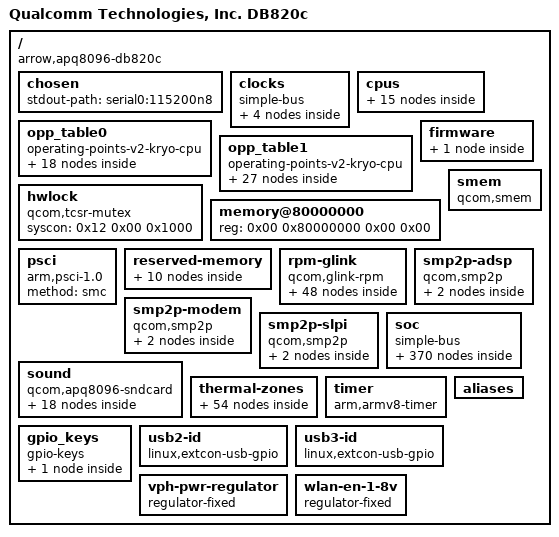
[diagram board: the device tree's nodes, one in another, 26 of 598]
/dts-v1/;

/ {
	interrupt-parent = <0x01>;
	#address-cells = <0x02>;
	#size-cells = <0x02>;
	model = "Qualcomm Technologies, Inc. DB820c";
	compatible = "arrow,apq8096-db820c\0qcom,apq8096-sbc\0qcom,apq8096";

	chosen {
		stdout-path = "serial0:115200n8";
	};

	clocks {
		compatible = "simple-bus";

		xo-board {
			compatible = "fixed-clock";
			#clock-cells = <0x00>;
			clock-frequency = <0x124f800>;
			clock-output-names = "xo_board";
			phandle = <0x29>;
		};

		sleep-clk {
			compatible = "fixed-clock";
			#clock-cells = <0x00>;
			clock-frequency = <0x7ffc>;
			clock-output-names = "sleep_clk";
			phandle = <0xaa>;
		};

		divclk4 {
			compatible = "fixed-clock";
			#clock-cells = <0x00>;
			clock-frequency = <0x8000>;
			clock-output-names = "divclk4";
			pinctrl-names = "default";
			pinctrl-0 = <0x02>;
			phandle = <0x7c>;
		};

		divclk1 {
			compatible = "gpio-gate-clock";
			pinctrl-0 = <0x03>;
			pinctrl-names = "default";
			clocks = <0x04 0x2e>;
			#clock-cells = <0x00>;
			enable-gpios = <0x05 0x0f 0x00>;
			phandle = <0x95>;
		};
	};

	cpus {
		#address-cells = <0x02>;
		#size-cells = <0x00>;

		cpu@0 {
			device_type = "cpu";
			compatible = "qcom,kryo";
			reg = <0x00 0x00>;
			enable-method = "psci";
			cpu-idle-states = <0x06>;
			capacity-dmips-mhz = <0x400>;
			clocks = <0x07 0x00>;
			operating-points-v2 = <0x08>;
			#cooling-cells = <0x02>;
			next-level-cache = <0x09>;
			phandle = <0x0c>;

			l2-cache {
				compatible = "cache";
				cache-level = <0x02>;
				phandle = <0x09>;
			};
		};

		cpu@1 {
			device_type = "cpu";
			compatible = "qcom,kryo";
			reg = <0x00 0x01>;
			enable-method = "psci";
			cpu-idle-states = <0x06>;
			capacity-dmips-mhz = <0x400>;
			clocks = <0x07 0x00>;
			operating-points-v2 = <0x08>;
			#cooling-cells = <0x02>;
			next-level-cache = <0x09>;
			phandle = <0x0d>;
		};

		cpu@100 {
			device_type = "cpu";
			compatible = "qcom,kryo";
			reg = <0x00 0x100>;
			enable-method = "psci";
			cpu-idle-states = <0x06>;
			capacity-dmips-mhz = <0x400>;
			clocks = <0x07 0x01>;
			operating-points-v2 = <0x0a>;
			#cooling-cells = <0x02>;
			next-level-cache = <0x0b>;
			phandle = <0x0e>;

			l2-cache {
				compatible = "cache";
				cache-level = <0x02>;
				phandle = <0x0b>;
			};
		};

		cpu@101 {
			device_type = "cpu";
			compatible = "qcom,kryo";
			reg = <0x00 0x101>;
			enable-method = "psci";
			cpu-idle-states = <0x06>;
			capacity-dmips-mhz = <0x400>;
			clocks = <0x07 0x01>;
			operating-points-v2 = <0x0a>;
			#cooling-cells = <0x02>;
			next-level-cache = <0x0b>;
			phandle = <0x0f>;
		};

		cpu-map {

			cluster0 {

				core0 {
					cpu = <0x0c>;
				};

				core1 {
					cpu = <0x0d>;
				};
			};

			cluster1 {

				core0 {
					cpu = <0x0e>;
				};

				core1 {
					cpu = <0x0f>;
				};
			};
		};

		idle-states {
			entry-method = "psci";

			cpu-sleep-0 {
				compatible = "arm,idle-state";
				idle-state-name = "standalone-power-collapse";
				arm,psci-suspend-param = <0x04>;
				entry-latency-us = <0x82>;
				exit-latency-us = <0x50>;
				min-residency-us = <0x12c>;
				phandle = <0x06>;
			};
		};
	};

	opp_table0 {
		compatible = "operating-points-v2-kryo-cpu";
		nvmem-cells = <0x10>;
		opp-shared;
		phandle = <0x08>;

		opp-307200000 {
			opp-hz = <0x00 0x124f8000>;
			opp-supported-hw = <0x07>;
			clock-latency-ns = <0x30d40>;
		};

		opp-422400000 {
			opp-hz = <0x00 0x192d5000>;
			opp-supported-hw = <0x07>;
			clock-latency-ns = <0x30d40>;
		};

		opp-480000000 {
			opp-hz = <0x00 0x1c9c3800>;
			opp-supported-hw = <0x07>;
			clock-latency-ns = <0x30d40>;
		};

		opp-556800000 {
			opp-hz = <0x00 0x21301800>;
			opp-supported-hw = <0x07>;
			clock-latency-ns = <0x30d40>;
		};

		opp-652800000 {
			opp-hz = <0x00 0x26e8f000>;
			opp-supported-hw = <0x07>;
			clock-latency-ns = <0x30d40>;
		};

		opp-729600000 {
			opp-hz = <0x00 0x2b7cd000>;
			opp-supported-hw = <0x07>;
			clock-latency-ns = <0x30d40>;
		};

		opp-844800000 {
			opp-hz = <0x00 0x325aa000>;
			opp-supported-hw = <0x07>;
			clock-latency-ns = <0x30d40>;
		};

		opp-960000000 {
			opp-hz = <0x00 0x39387000>;
			opp-supported-hw = <0x07>;
			clock-latency-ns = <0x30d40>;
		};

		opp-1036800000 {
			opp-hz = <0x00 0x3dcc5000>;
			opp-supported-hw = <0x07>;
			clock-latency-ns = <0x30d40>;
		};

		opp-1113600000 {
			opp-hz = <0x00 0x42603000>;
			opp-supported-hw = <0x07>;
			clock-latency-ns = <0x30d40>;
		};

		opp-1190400000 {
			opp-hz = <0x00 0x46f41000>;
			opp-supported-hw = <0x07>;
			clock-latency-ns = <0x30d40>;
		};

		opp-1228800000 {
			opp-hz = <0x00 0x493e0000>;
			opp-supported-hw = <0x07>;
			clock-latency-ns = <0x30d40>;
		};

		opp-1324800000 {
			opp-hz = <0x00 0x4ef6d800>;
			opp-supported-hw = <0x05>;
			clock-latency-ns = <0x30d40>;
		};

		opp-1363200000 {
			opp-hz = <0x00 0x5140c800>;
			opp-supported-hw = <0x02>;
			clock-latency-ns = <0x30d40>;
		};

		opp-1401600000 {
			opp-hz = <0x00 0x538ab800>;
			opp-supported-hw = <0x05>;
			clock-latency-ns = <0x30d40>;
		};

		opp-1478400000 {
			opp-hz = <0x00 0x581e9800>;
			opp-supported-hw = <0x01>;
			clock-latency-ns = <0x30d40>;
		};

		opp-1497600000 {
			opp-hz = <0x00 0x59439000>;
			opp-supported-hw = <0x04>;
			clock-latency-ns = <0x30d40>;
		};

		opp-1593600000 {
			opp-hz = <0x00 0x5efc6800>;
			opp-supported-hw = <0x01>;
			clock-latency-ns = <0x30d40>;
		};
	};

	opp_table1 {
		compatible = "operating-points-v2-kryo-cpu";
		nvmem-cells = <0x10>;
		opp-shared;
		phandle = <0x0a>;

		opp-307200000 {
			opp-hz = <0x00 0x124f8000>;
			opp-supported-hw = <0x07>;
			clock-latency-ns = <0x30d40>;
		};

		opp-403200000 {
			opp-hz = <0x00 0x18085800>;
			opp-supported-hw = <0x07>;
			clock-latency-ns = <0x30d40>;
		};

		opp-480000000 {
			opp-hz = <0x00 0x1c9c3800>;
			opp-supported-hw = <0x07>;
			clock-latency-ns = <0x30d40>;
		};

		opp-556800000 {
			opp-hz = <0x00 0x21301800>;
			opp-supported-hw = <0x07>;
			clock-latency-ns = <0x30d40>;
		};

		opp-652800000 {
			opp-hz = <0x00 0x26e8f000>;
			opp-supported-hw = <0x07>;
			clock-latency-ns = <0x30d40>;
		};

		opp-729600000 {
			opp-hz = <0x00 0x2b7cd000>;
			opp-supported-hw = <0x07>;
			clock-latency-ns = <0x30d40>;
		};

		opp-806400000 {
			opp-hz = <0x00 0x3010b000>;
			opp-supported-hw = <0x07>;
			clock-latency-ns = <0x30d40>;
		};

		opp-883200000 {
			opp-hz = <0x00 0x34a49000>;
			opp-supported-hw = <0x07>;
			clock-latency-ns = <0x30d40>;
		};

		opp-940800000 {
			opp-hz = <0x00 0x38137800>;
			opp-supported-hw = <0x07>;
			clock-latency-ns = <0x30d40>;
		};

		opp-1036800000 {
			opp-hz = <0x00 0x3dcc5000>;
			opp-supported-hw = <0x07>;
			clock-latency-ns = <0x30d40>;
		};

		opp-1113600000 {
			opp-hz = <0x00 0x42603000>;
			opp-supported-hw = <0x07>;
			clock-latency-ns = <0x30d40>;
		};

		opp-1190400000 {
			opp-hz = <0x00 0x46f41000>;
			opp-supported-hw = <0x07>;
			clock-latency-ns = <0x30d40>;
		};

		opp-1248000000 {
			opp-hz = <0x00 0x4a62f800>;
			opp-supported-hw = <0x07>;
			clock-latency-ns = <0x30d40>;
		};

		opp-1324800000 {
			opp-hz = <0x00 0x4ef6d800>;
			opp-supported-hw = <0x07>;
			clock-latency-ns = <0x30d40>;
		};

		opp-1401600000 {
			opp-hz = <0x00 0x538ab800>;
			opp-supported-hw = <0x07>;
			clock-latency-ns = <0x30d40>;
		};

		opp-1478400000 {
			opp-hz = <0x00 0x581e9800>;
			opp-supported-hw = <0x07>;
			clock-latency-ns = <0x30d40>;
		};

		opp-1555200000 {
			opp-hz = <0x00 0x5cb27800>;
			opp-supported-hw = <0x07>;
			clock-latency-ns = <0x30d40>;
		};

		opp-1632000000 {
			opp-hz = <0x00 0x61465800>;
			opp-supported-hw = <0x07>;
			clock-latency-ns = <0x30d40>;
		};

		opp-1708800000 {
			opp-hz = <0x00 0x65da3800>;
			opp-supported-hw = <0x07>;
			clock-latency-ns = <0x30d40>;
		};

		opp-1785600000 {
			opp-hz = <0x00 0x6a6e1800>;
			opp-supported-hw = <0x07>;
			clock-latency-ns = <0x30d40>;
		};

		opp-1804800000 {
			opp-hz = <0x00 0x6b931000>;
			opp-supported-hw = <0x06>;
			clock-latency-ns = <0x30d40>;
		};

		opp-1824000000 {
			opp-hz = <0x00 0x6cb80800>;
			opp-supported-hw = <0x01>;
			clock-latency-ns = <0x30d40>;
		};

		opp-1900800000 {
			opp-hz = <0x00 0x714be800>;
			opp-supported-hw = <0x04>;
			clock-latency-ns = <0x30d40>;
		};

		opp-1920000000 {
			opp-hz = <0x00 0x7270e000>;
			opp-supported-hw = <0x01>;
			clock-latency-ns = <0x30d40>;
		};

		opp-1996800000 {
			opp-hz = <0x00 0x7704c000>;
			opp-supported-hw = <0x01>;
			clock-latency-ns = <0x30d40>;
		};

		opp-2073600000 {
			opp-hz = <0x00 0x7b98a000>;
			opp-supported-hw = <0x01>;
			clock-latency-ns = <0x30d40>;
		};

		opp-2150400000 {
			opp-hz = <0x00 0x802c8000>;
			opp-supported-hw = <0x01>;
			clock-latency-ns = <0x30d40>;
		};
	};

	firmware {

		scm {
			compatible = "qcom,scm-msm8996";
			qcom,dload-mode = <0x11 0x13000>;
		};
	};

	hwlock {
		compatible = "qcom,tcsr-mutex";
		syscon = <0x12 0x00 0x1000>;
		#hwlock-cells = <0x01>;
		phandle = <0x1d>;
	};

	memory@80000000 {
		device_type = "memory";
		reg = <0x00 0x80000000 0x00 0x00>;
	};

	psci {
		compatible = "arm,psci-1.0";
		method = "smc";
	};

	reserved-memory {
		#address-cells = <0x02>;
		#size-cells = <0x02>;
		ranges;

		mba@91500000 {
			reg = <0x00 0x91500000 0x00 0x200000>;
			no-map;
			phandle = <0xab>;
		};

		slpi@90b00000 {
			reg = <0x00 0x90b00000 0x00 0xa00000>;
			no-map;
			phandle = <0xac>;
		};

		venus@90400000 {
			reg = <0x00 0x90400000 0x00 0x700000>;
			no-map;
			phandle = <0x4c>;
		};

		adsp@8ea00000 {
			reg = <0x00 0x8ea00000 0x00 0x1a00000>;
			no-map;
			phandle = <0x97>;
		};

		mpss@88800000 {
			reg = <0x00 0x88800000 0x00 0x6200000>;
			no-map;
			phandle = <0xad>;
		};

		smem-mem@86000000 {
			reg = <0x00 0x86000000 0x00 0x200000>;
			no-map;
			phandle = <0x1c>;
		};

		memory@85800000 {
			reg = <0x00 0x85800000 0x00 0x800000>;
			no-map;
		};

		memory@86200000 {
			reg = <0x00 0x86200000 0x00 0x2600000>;
			no-map;
		};

		rmtfs@86700000 {
			compatible = "qcom,rmtfs-mem";
			size = <0x00 0x200000>;
			alloc-ranges = <0x00 0xa0000000 0x00 0x2000000>;
			no-map;
			qcom,client-id = <0x01>;
			qcom,vmid = <0x0f>;
		};

		gpu@8f200000 {
			compatible = "shared-dma-pool";
			reg = <0x00 0x90b00000 0x00 0xa00000>;
			no-map;
			phandle = <0x32>;
		};
	};

	rpm-glink {
		compatible = "qcom,glink-rpm";
		interrupts = <0x00 0xa8 0x01>;
		qcom,rpm-msg-ram = <0x13>;
		mboxes = <0x14 0x00>;

		rpm-requests {
			compatible = "qcom,rpm-msm8996";
			qcom,glink-channels = "rpm_requests";
			phandle = <0xae>;

			qcom,rpmcc {
				compatible = "qcom,rpmcc-msm8996";
				#clock-cells = <0x01>;
				phandle = <0x04>;
			};

			power-controller {
				compatible = "qcom,msm8996-rpmpd";
				#power-domain-cells = <0x01>;
				operating-points-v2 = <0x15>;
				phandle = <0x99>;

				opp-table {
					compatible = "operating-points-v2";
					phandle = <0x15>;

					opp1 {
						opp-level = <0x01>;
						phandle = <0xaf>;
					};

					opp2 {
						opp-level = <0x02>;
						phandle = <0xb0>;
					};

					opp3 {
						opp-level = <0x03>;
						phandle = <0xb1>;
					};

					opp4 {
						opp-level = <0x04>;
						phandle = <0xb2>;
					};

					opp5 {
						opp-level = <0x05>;
						phandle = <0xb3>;
					};

					opp6 {
						opp-level = <0x06>;
						phandle = <0xb4>;
					};
				};
			};

			pm8994-regulators {
				compatible = "qcom,rpm-pm8994-regulators";
				vdd_s1-supply = <0x16>;
				vdd_s2-supply = <0x16>;
				vdd_s3-supply = <0x16>;
				vdd_s4-supply = <0x16>;
				vdd_s5-supply = <0x16>;
				vdd_s6-supply = <0x16>;
				vdd_s7-supply = <0x16>;
				vdd_s8-supply = <0x16>;
				vdd_s9-supply = <0x16>;
				vdd_s10-supply = <0x16>;
				vdd_s11-supply = <0x16>;
				vdd_s12-supply = <0x16>;
				vdd_l1-supply = <0x17>;
				vdd_l2_l26_l28-supply = <0x18>;
				vdd_l3_l11-supply = <0x18>;
				vdd_l4_l27_l31-supply = <0x18>;
				vdd_l5_l7-supply = <0x19>;
				vdd_l6_l12_l32-supply = <0x19>;
				vdd_l8_l16_l30-supply = <0x16>;
				vdd_l9_l10_l18_l22-supply = <0x1a>;
				vdd_l13_l19_l23_l24-supply = <0x1a>;
				vdd_l14_l15-supply = <0x19>;
				vdd_l17_l29-supply = <0x1a>;
				vdd_l20_l21-supply = <0x1a>;
				vdd_l25-supply = <0x18>;
				vdd_lvs1_lvs2-supply = <0x1b>;

				s3 {
					regulator-name = "vreg_s3a_1p3";
					regulator-min-microvolt = <0x13d620>;
					regulator-max-microvolt = <0x13d620>;
					phandle = <0x18>;
				};

				s4 {
					regulator-name = "vreg_s4a_1p8";
					regulator-min-microvolt = <0x1b7740>;
					regulator-max-microvolt = <0x1b7740>;
					regulator-always-on;
					phandle = <0x1b>;
				};

				s5 {
					regulator-name = "vreg_s5a_2p15";
					regulator-min-microvolt = <0x20ce70>;
					regulator-max-microvolt = <0x20ce70>;
					phandle = <0x19>;
				};

				s7 {
					regulator-name = "vreg_s7a_1p0";
					regulator-min-microvolt = "\0\f5";
					regulator-max-microvolt = "\0\f5";
					phandle = <0xb5>;
				};

				l1 {
					regulator-name = "vreg_l1a_1p0";
					regulator-min-microvolt = <0xf4240>;
					regulator-max-microvolt = <0xf4240>;
					phandle = <0xb6>;
				};

				l2 {
					regulator-name = "vreg_l2a_1p25";
					regulator-min-microvolt = <0x1312d0>;
					regulator-max-microvolt = <0x1312d0>;
					phandle = <0x48>;
				};

				l3 {
					regulator-name = "vreg_l3a_0p875";
					regulator-min-microvolt = <0xcf850>;
					regulator-max-microvolt = <0xcf850>;
					phandle = <0xb7>;
				};

				l4 {
					regulator-name = "vreg_l4a_1p225";
					regulator-min-microvolt = <0x12b128>;
					regulator-max-microvolt = <0x12b128>;
					phandle = <0xb8>;
				};

				l6 {
					regulator-name = "vreg_l6a_1p2";
					regulator-min-microvolt = <0x124f80>;
					regulator-max-microvolt = <0x124f80>;
					phandle = <0xb9>;
				};

				l8 {
					regulator-name = "vreg_l8a_1p8";
					regulator-min-microvolt = <0x1b7740>;
					regulator-max-microvolt = <0x1b7740>;
					phandle = <0xba>;
				};

				l9 {
					regulator-name = "vreg_l9a_1p8";
					regulator-min-microvolt = <0x1b7740>;
					regulator-max-microvolt = <0x1b7740>;
					phandle = <0xbb>;
				};

				l10 {
					regulator-name = "vreg_l10a_1p8";
					regulator-min-microvolt = <0x1b7740>;
					regulator-max-microvolt = <0x1b7740>;
					phandle = <0xbc>;
				};

				l11 {
					regulator-name = "vreg_l11a_1p15";
					regulator-min-microvolt = <0x118c30>;
					regulator-max-microvolt = <0x118c30>;
					phandle = <0xbd>;
				};

				l12 {
					regulator-name = "vreg_l12a_1p8";
					regulator-min-microvolt = <0x1b7740>;
					regulator-max-microvolt = <0x1b7740>;
					phandle = <0x20>;
				};

				l13 {
					regulator-name = "vreg_l13a_2p95";
					regulator-min-microvolt = <0x1b7740>;
					regulator-max-microvolt = <0x2d0370>;
					phandle = <0x78>;
				};

				l14 {
					regulator-name = "vreg_l14a_1p8";
					regulator-min-microvolt = <0x1b7740>;
					regulator-max-microvolt = <0x1b7740>;
					phandle = <0xbe>;
				};

				l15 {
					regulator-name = "vreg_l15a_1p8";
					regulator-min-microvolt = <0x1b7740>;
					regulator-max-microvolt = <0x1b7740>;
					phandle = <0xbf>;
				};

				l16 {
					regulator-name = "vreg_l16a_2p7";
					regulator-min-microvolt = <0x2932e0>;
					regulator-max-microvolt = <0x2932e0>;
					phandle = <0xc0>;
				};

				l17 {
					regulator-name = "vreg_l17a_2p8";
					regulator-min-microvolt = <0x2625a0>;
					regulator-max-microvolt = <0x2625a0>;
					phandle = <0xc1>;
				};

				l18 {
					regulator-name = "vreg_l18a_2p85";
					regulator-min-microvolt = <0x2932e0>;
					regulator-max-microvolt = <0x2c4020>;
					phandle = <0xc2>;
				};

				l19 {
					regulator-name = "vreg_l19a_2p8";
					regulator-min-microvolt = <0x2dc6c0>;
					regulator-max-microvolt = <0x2dc6c0>;
					phandle = <0xc3>;
				};

				l20 {
					regulator-name = "vreg_l20a_2p95";
					regulator-min-microvolt = <0x2d0370>;
					regulator-max-microvolt = <0x2d0370>;
					regulator-allow-set-load;
					phandle = <0x44>;
				};

				l21 {
					regulator-name = "vreg_l21a_2p95";
					regulator-min-microvolt = <0x2d0370>;
					regulator-max-microvolt = <0x2d0370>;
					regulator-allow-set-load;
					regulator-system-load = <0x30d40>;
					phandle = <0x77>;
				};

				l22 {
					regulator-name = "vreg_l22a_3p0";
					regulator-min-microvolt = <0x325aa0>;
					regulator-max-microvolt = <0x325aa0>;
					phandle = <0xc4>;
				};

				l23 {
					regulator-name = "vreg_l23a_2p8";
					regulator-min-microvolt = <0x2ab980>;
					regulator-max-microvolt = <0x2ab980>;
					phandle = <0xc5>;
				};

				l24 {
					regulator-name = "vreg_l24a_3p075";
					regulator-min-microvolt = <0x2eebb8>;
					regulator-max-microvolt = <0x2eebb8>;
					phandle = <0x6f>;
				};

				l25 {
					regulator-name = "vreg_l25a_1p2";
					regulator-min-microvolt = <0x124f80>;
					regulator-max-microvolt = <0x124f80>;
					regulator-allow-set-load;
					phandle = <0x45>;
				};

				l27 {
					regulator-name = "vreg_l26a_0p8";
					regulator-min-microvolt = <0xf4240>;
					regulator-max-microvolt = <0xf4240>;
					phandle = <0xc6>;
				};

				l28 {
					regulator-name = "vreg_l28a_0p925";
					regulator-min-microvolt = <0xe1d48>;
					regulator-max-microvolt = <0xe1d48>;
					regulator-allow-set-load;
					phandle = <0x1f>;
				};

				l29 {
					regulator-name = "vreg_l29a_2p8";
					regulator-min-microvolt = <0x2ab980>;
					regulator-max-microvolt = <0x2ab980>;
					phandle = <0xc7>;
				};

				l30 {
					regulator-name = "vreg_l30a_1p8";
					regulator-min-microvolt = <0x1b7740>;
					regulator-max-microvolt = <0x1b7740>;
					phandle = <0xc8>;
				};

				l32 {
					regulator-name = "vreg_l32a_1p8";
					regulator-min-microvolt = <0x1b7740>;
					regulator-max-microvolt = <0x1b7740>;
					phandle = <0xc9>;
				};

				lvs1 {
					regulator-name = "vreg_lvs1a_1p8";
					phandle = <0xca>;
				};

				lvs2 {
					regulator-name = "vreg_lvs2a_1p8";
					phandle = <0xcb>;
				};
			};

			pmi8994-regulators {
				compatible = "qcom,rpm-pmi8994-regulators";
				vdd_s1-supply = <0x16>;
				vdd_s2-supply = <0x16>;
				vdd_s3-supply = <0x16>;
				vdd_bst_byp-supply = <0x16>;

				boost-bypass {
					regulator-name = "vph_pwr_bbyp";
					regulator-min-microvolt = <0x325aa0>;
					regulator-max-microvolt = <0x325aa0>;
					phandle = <0x1a>;
				};

				s1 {
					regulator-name = "vreg_s1b_1p025";
					regulator-min-microvolt = <0xfa3e8>;
					regulator-max-microvolt = <0xfa3e8>;
					phandle = <0x17>;
				};
			};
		};
	};

	smem {
		compatible = "qcom,smem";
		memory-region = <0x1c>;
		hwlocks = <0x1d 0x03>;
	};

	smp2p-adsp {
		compatible = "qcom,smp2p";
		qcom,smem = <0x1bb 0x1ad>;
		interrupts = <0x00 0x9e 0x01>;
		mboxes = <0x14 0x0a>;
		qcom,local-pid = <0x00>;
		qcom,remote-pid = <0x02>;

		master-kernel {
			qcom,entry-name = "master-kernel";
			#qcom,smem-state-cells = <0x01>;
			phandle = <0x98>;
		};

		slave-kernel {
			qcom,entry-name = "slave-kernel";
			interrupt-controller;
			#interrupt-cells = <0x02>;
			phandle = <0x96>;
		};
	};

	smp2p-modem {
		compatible = "qcom,smp2p";
		qcom,smem = <0x1b3 0x1ac>;
		interrupts = <0x00 0x1c3 0x01>;
		mboxes = <0x14 0x0e>;
		qcom,local-pid = <0x00>;
		qcom,remote-pid = <0x01>;

		master-kernel {
			qcom,entry-name = "master-kernel";
			#qcom,smem-state-cells = <0x01>;
			phandle = <0xcc>;
		};

		slave-kernel {
			qcom,entry-name = "slave-kernel";
			interrupt-controller;
			#interrupt-cells = <0x02>;
			phandle = <0xcd>;
		};
	};

	smp2p-slpi {
		compatible = "qcom,smp2p";
		qcom,smem = <0x1e1 0x1ae>;
		interrupts = <0x00 0xb2 0x01>;
		mboxes = <0x14 0x1a>;
		qcom,local-pid = <0x00>;
		qcom,remote-pid = <0x03>;

		slave-kernel {
			qcom,entry-name = "slave-kernel";
			interrupt-controller;
			#interrupt-cells = <0x02>;
			phandle = <0xce>;
		};

		master-kernel {
			qcom,entry-name = "master-kernel";
			#qcom,smem-state-cells = <0x01>;
			phandle = <0xcf>;
		};
	};

	soc {
		#address-cells = <0x01>;
		#size-cells = <0x01>;
		ranges = <0x00 0x00 0x00 0xffffffff>;
		compatible = "simple-bus";
		phandle = <0xd0>;

		phy@34000 {
			compatible = "qcom,msm8996-qmp-pcie-phy";
			reg = <0x34000 0x488>;
			#clock-cells = <0x01>;
			#address-cells = <0x01>;
			#size-cells = <0x01>;
			ranges;
			clocks = <0x1e 0xc0 0x1e 0xbf 0x1e 0xd8>;
			clock-names = "aux\0cfg_ahb\0ref";
			resets = <0x1e 0x55 0x1e 0x65 0x1e 0x66>;
			reset-names = "phy\0common\0cfg";
			status = "okay";
			vdda-phy-supply = <0x1f>;
			vdda-pll-supply = <0x20>;
			phandle = <0xd1>;

			phy@35000 {
				reg = <0x35000 0x130 0x35200 0x200 0x35400 0x1dc>;
				#phy-cells = <0x00>;
				clock-output-names = "pcie_0_pipe_clk_src";
				clocks = <0x1e 0xb4>;
				clock-names = "pipe0";
				resets = <0x1e 0x50>;
				reset-names = "lane0";
				phandle = <0x39>;
			};

			phy@36000 {
				reg = <0x36000 0x130 0x36200 0x200 0x36400 0x1dc>;
				#phy-cells = <0x00>;
				clock-output-names = "pcie_1_pipe_clk_src";
				clocks = <0x1e 0xb9>;
				clock-names = "pipe1";
				resets = <0x1e 0x52>;
				reset-names = "lane1";
				phandle = <0x3d>;
			};

			phy@37000 {
				reg = <0x37000 0x130 0x37200 0x200 0x37400 0x1dc>;
				#phy-cells = <0x00>;
				clock-output-names = "pcie_2_pipe_clk_src";
				clocks = <0x1e 0xbe>;
				clock-names = "pipe2";
				resets = <0x1e 0x54>;
				reset-names = "lane2";
				phandle = <0x40>;
			};
		};

		sram@68000 {
			compatible = "qcom,rpm-msg-ram";
			reg = <0x68000 0x6000>;
			phandle = <0x13>;
		};

		qfprom@74000 {
			compatible = "qcom,qfprom";
			reg = <0x74000 0x8ff>;
			#address-cells = <0x01>;
			#size-cells = <0x01>;

			hstx_trim@24e {
				reg = <0x24e 0x02>;
				bits = <0x05 0x04>;
				phandle = <0x6e>;
			};

			hstx_trim@24f {
				reg = <0x24f 0x01>;
				bits = <0x01 0x04>;
				phandle = <0x70>;
			};

			speedbin@133 {
				reg = <0x133 0x01>;
				bits = <0x05 0x03>;
				phandle = <0x10>;
			};
		};

		rng@83000 {
			compatible = "qcom,prng-ee";
			reg = <0x83000 0x1000>;
			clocks = <0x1e 0x98>;
			clock-names = "core";
			phandle = <0xd2>;
		};

		clock-controller@300000 {
			compatible = "qcom,gcc-msm8996";
			#clock-cells = <0x01>;
			#reset-cells = <0x01>;
			#power-domain-cells = <0x01>;
			reg = <0x300000 0x90000>;
			clocks = <0x04 0x4a>;
			clock-names = "cxo2";
			phandle = <0x1e>;
		};

		thermal-sensor@4a9000 {
			compatible = "qcom,msm8996-tsens\0qcom,tsens-v2";
			reg = <0x4a9000 0x1000 0x4a8000 0x1000>;
			#qcom,sensors = <0x0d>;
			interrupts = <0x00 0x1ca 0x04 0x00 0x1bd 0x04>;
			interrupt-names = "uplow\0critical";
			#thermal-sensor-cells = <0x01>;
			phandle = <0xa0>;
		};

		thermal-sensor@4ad000 {
			compatible = "qcom,msm8996-tsens\0qcom,tsens-v2";
			reg = <0x4ad000 0x1000 0x4ac000 0x1000>;
			#qcom,sensors = <0x08>;
			interrupts = <0x00 0xb8 0x04 0x00 0x1ae 0x04>;
			interrupt-names = "uplow\0critical";
			#thermal-sensor-cells = <0x01>;
			phandle = <0xa1>;
		};

		syscon@740000 {
			compatible = "syscon";
			reg = <0x740000 0x40000>;
			phandle = <0x12>;
		};

		syscon@7a0000 {
			compatible = "qcom,tcsr-msm8996\0syscon";
			reg = <0x7a0000 0x18000>;
			phandle = <0x11>;
		};

		clock-controller@8c0000 {
			compatible = "qcom,mmcc-msm8996";
			#clock-cells = <0x01>;
			#reset-cells = <0x01>;
			#power-domain-cells = <0x01>;
			reg = <0x8c0000 0x40000>;
			assigned-clocks = <0x21 0x0f 0x21 0x03 0x21 0x07 0x21 0x09 0x21 0x0b>;
			assigned-clock-rates = <0x25317c00 0x30479e80 0x3a699d00 0x39387000 0x312c8040>;
			vdd-gfx-supply = <0x22>;
			phandle = <0x21>;
		};

		mdss@900000 {
			compatible = "qcom,mdss";
			reg = <0x900000 0x1000 0x9b0000 0x1040 0x9b8000 0x1040>;
			reg-names = "mdss_phys\0vbif_phys\0vbif_nrt_phys";
			power-domains = <0x21 0x0d>;
			interrupts = <0x00 0x53 0x04>;
			interrupt-controller;
			#interrupt-cells = <0x01>;
			clocks = <0x21 0x74>;
			clock-names = "iface";
			#address-cells = <0x01>;
			#size-cells = <0x01>;
			ranges;
			status = "okay";
			phandle = <0x23>;

			mdp@901000 {
				compatible = "qcom,mdp5";
				reg = <0x901000 0x90000>;
				reg-names = "mdp_phys";
				interrupt-parent = <0x23>;
				interrupts = <0x00 0x04>;
				clocks = <0x21 0x74 0x21 0x76 0x21 0x79 0x21 0x5c 0x21 0x7b>;
				clock-names = "iface\0bus\0core\0iommu\0vsync";
				iommus = <0x24 0x00>;
				assigned-clocks = <0x21 0x79 0x21 0x7b>;
				assigned-clock-rates = <0x11e1a300 0x124f800>;
				status = "okay";
				phandle = <0xd3>;

				ports {
					#address-cells = <0x01>;
					#size-cells = <0x00>;

					port@0 {
						reg = <0x00>;

						endpoint {
							remote-endpoint = <0x25>;
							phandle = <0x2f>;
						};
					};

					port@1 {
						reg = <0x01>;

						endpoint {
							remote-endpoint = <0x26>;
							phandle = <0x28>;
						};
					};
				};
			};

			dsi@994000 {
				compatible = "qcom,mdss-dsi-ctrl";
				reg = <0x994000 0x400>;
				reg-names = "dsi_ctrl";
				interrupt-parent = <0x23>;
				interrupts = <0x04 0x04>;
				clocks = <0x21 0x79 0x21 0x7d 0x21 0x74 0x21 0x76 0x21 0x41 0x21 0x77 0x21 0x7f>;
				clock-names = "mdp_core\0byte\0iface\0bus\0core_mmss\0pixel\0core";
				phys = <0x27>;
				phy-names = "dsi";
				status = "disabled";
				#address-cells = <0x01>;
				#size-cells = <0x00>;
				phandle = <0xd4>;

				ports {
					#address-cells = <0x01>;
					#size-cells = <0x00>;

					port@0 {
						reg = <0x00>;

						endpoint {
							remote-endpoint = <0x28>;
							phandle = <0x26>;
						};
					};

					port@1 {
						reg = <0x01>;

						endpoint {
							phandle = <0xd5>;
						};
					};
				};
			};

			dsi-phy@994400 {
				compatible = "qcom,dsi-phy-14nm";
				reg = <0x994400 0x100 0x994500 0x300 0x994800 0x188>;
				reg-names = "dsi_phy\0dsi_phy_lane\0dsi_pll";
				#clock-cells = <0x01>;
				#phy-cells = <0x00>;
				clocks = <0x21 0x74 0x29>;
				clock-names = "iface\0ref";
				status = "disabled";
				phandle = <0x27>;
			};

			hdmi-tx@9a0000 {
				compatible = "qcom,hdmi-tx-8996";
				reg = <0x9a0000 0x50c 0x70000 0x6158 0x9e0000 0xfff>;
				reg-names = "core_physical\0qfprom_physical\0hdcp_physical";
				interrupt-parent = <0x23>;
				interrupts = <0x08 0x04>;
				clocks = <0x21 0x79 0x21 0x74 0x21 0x7c 0x21 0x75 0x21 0x7a>;
				clock-names = "mdp_core\0iface\0core\0alt_iface\0extp";
				phys = <0x2a>;
				phy-names = "hdmi_phy";
				#sound-dai-cells = <0x01>;
				status = "okay";
				pinctrl-names = "default\0sleep";
				pinctrl-0 = <0x2b 0x2c>;
				pinctrl-1 = <0x2d 0x2e>;
				core-vdda-supply = <0x20>;
				core-vcc-supply = <0x1b>;
				phandle = <0x9e>;

				ports {
					#address-cells = <0x01>;
					#size-cells = <0x00>;

					port@0 {
						reg = <0x00>;

						endpoint {
							remote-endpoint = <0x2f>;
							phandle = <0x25>;
						};
					};
				};
			};

			hdmi-phy@9a0600 {
				#phy-cells = <0x00>;
				compatible = "qcom,hdmi-phy-8996";
				reg = <0x9a0600 0x1c4 0x9a0a00 0x124 0x9a0c00 0x124 0x9a0e00 0x124 0x9a1000 0x124 0x9a1200 0xc8>;
				reg-names = "hdmi_pll\0hdmi_tx_l0\0hdmi_tx_l1\0hdmi_tx_l2\0hdmi_tx_l3\0hdmi_phy";
				clocks = <0x21 0x74 0x1e 0xd6>;
				clock-names = "iface\0ref";
				status = "okay";
				vddio-supply = <0x20>;
				vcca-supply = <0x1f>;
				phandle = <0x2a>;
			};
		};

		gpu@b00000 {
			compatible = "qcom,adreno-530.2\0qcom,adreno";
			#stream-id-cells = <0x10>;
			reg = <0xb00000 0x3f000>;
			reg-names = "kgsl_3d0_reg_memory";
			interrupts = <0x00 0x12c 0x04>;
			clocks = <0x21 0x66 0x21 0x68 0x21 0x67 0x1e 0xa8 0x1e 0x5a>;
			clock-names = "core\0iface\0rbbmtimer\0mem\0mem_iface";
			power-domains = <0x21 0x0e>;
			iommus = <0x30 0x00>;
			nvmem-cells = <0x10>;
			nvmem-cell-names = "speed_bin";
			operating-points-v2 = <0x31>;
			status = "okay";
			#cooling-cells = <0x02>;
			phandle = <0xa3>;

			opp-table {
				compatible = "operating-points-v2";
				phandle = <0x31>;

				opp-624000000 {
					opp-hz = <0x00 0x25317c00>;
					opp-supported-hw = <0x09>;
				};

				opp-560000000 {
					opp-hz = <0x00 0x2160ec00>;
					opp-supported-hw = <0x0d>;
				};

				opp-510000000 {
					opp-hz = <0x00 0x1e65fb80>;
					opp-supported-hw = <0xff>;
				};

				opp-401800000 {
					opp-hz = <0x00 0x17f2fb40>;
					opp-supported-hw = <0xff>;
				};

				opp-315000000 {
					opp-hz = <0x00 0x12c684c0>;
					opp-supported-hw = <0xff>;
				};

				opp-214000000 {
					opp-hz = <0x00 0xcc16180>;
					opp-supported-hw = <0xff>;
				};

				opp-133000000 {
					opp-hz = <0x00 0x7ed6b40>;
					opp-supported-hw = <0xff>;
				};
			};

			zap-shader {
				memory-region = <0x32>;
			};
		};

		pinctrl@1010000 {
			compatible = "qcom,msm8996-pinctrl";
			reg = <0x1010000 0x300000>;
			interrupts = <0x00 0xd0 0x04>;
			gpio-controller;
			gpio-ranges = <0x33 0x00 0x00 0x96>;
			#gpio-cells = <0x02>;
			interrupt-controller;
			#interrupt-cells = <0x02>;
			gpio-line-names = "[SPI0_DOUT]\0[SPI0_DIN]\0[SPI0_CS]\0[SPI0_SCLK]\0[UART1_TxD]\0[UART1_RxD]\0[I2C1_SDA]\0[I2C1_SCL]\0GPIO-H\0TP93\0GPIO-G\0[MDP_VSYNC_S]\0NC\0[CSI0_MCLK]\0[CAM_MCLK1]\0[CSI1_MCLK]\0TP99\0[I2C2_SDA]\0[I2C2_SCL]\0[CCI_I2C_SDA1]\0[CCI_I2C_SCL1]\0FLASH_STROBE_EN\0FLASH_STROBE_TRIG\0GPIO-K\0GPIO-D\0GPIO-I\0GPIO-J\0BLSP6_I2C_SDA\0BLSP6_I2C_SCL\0GPIO-B\0GPIO30\0HDMI_CEC\0HDMI_DDC_CLOCK\0HDMI_DDC_DATA\0HDMI_HOT_PLUG_DETECT\0PCIE0_RST_N\0PCIE0_CLKREQ_N\0PCIE0_WAKE\0SD_CARD_DET_N\0TSIF1_SYNC\0W_DISABLE_N\0[BLSP9_UART_TX]\0[BLSP9_UART_RX]\0[BLSP2_UART_CTS_N]\0[BLSP2_UART_RFR_N]\0[BLSP3_UART_TX]\0[BLSP3_UART_RX]\0[I2C0_SDA]\0[I2C0_SCL]\0[UART0_TxD]\0[UART0_RxD]\0[UART0_CTS]\0[UART0_RTS]\0[CODEC_INT1_N]\0[CODEC_INT2_N]\0[BLSP7_I2C_SDA]\0[BLSP7_I2C_SCL]\0MI2S_MCLK\0[PCM_CLK]\0[PCM_FS]\0[PCM_DO]\0[PCM_DI]\0GPIO-E\0TP87\0[CODEC_RST_N]\0[PCM1_CLK]\0[PCM1_SYNC]\0[PCM1_DIN]\0[PCM1_DOUT]\0AUDIO_REF_CLK\0SLIMBUS_CLK\0SLIMBUS_DATA0\0SLIMBUS_DATA1\0NC\0NC\0NC\0NC\0TP94\0NC\0TP95\0GPIO-A\0TP88\0TP89\0TP90\0TP91\0[SD_DAT0]\0[SD_CMD]\0[SD_DAT3]\0[SD_SCLK]\0TSIF1_CLK\0TSIF1_EN\0TSIF1_DATA\0NC\0TSIF2_CLK\0TSIF2_EN\0TSIF2_DATA\0TSIF2_SYNC\0NC\0CAM1_STANDBY_N\0NC\0NC\0[LCD1_RESET_N]\0BOOT_CONFIG1\0USB_HUB_RESET\0CAM1_RST_N\0NC\0NC\0NC\0NC\0NC\0NC\0NC\0NC\0PMI8994_BUA\0PCIE2_RST_N\0PCIE2_CLKREQ_N\0PCIE2_WAKE\0SSC_IRQ_0\0SSC_IRQ_1\0SSC_IRQ_2\0NC\0GPIO121\0NC\0SSC_IRQ_6\0SSC_IRQ_7\0GPIO-C\0BOOT_CONFIG5\0NC\0NC\0BOOT_CONFIG7\0PCIE1_RST_N\0PCIE1_CLKREQ_N\0PCIE1_WAKE\0GPIO-L\0NC\0NC\0BOOT_CONFIG8\0NC\0NC\0GPS_SSBI2\0GPS_SSBI1\0NC\0NC\0NC\0BOOT_CONFIG6\0NC\0NC\0NC\0NC\0NC";
			phandle = <0x33>;

			blsp1-spi1-default {
				phandle = <0x7d>;

				spi {
					pins = "gpio0\0gpio1\0gpio3";
					function = "blsp_spi1";
					drive-strength = <0x0c>;
					bias-disable;
				};

				cs {
					pins = "gpio2";
					function = "gpio";
					drive-strength = <0x10>;
					bias-disable;
					output-high;
				};
			};

			blsp1-spi1-sleep {
				pins = "gpio0\0gpio1\0gpio2\0gpio3";
				function = "gpio";
				drive-strength = <0x02>;
				bias-pull-down;
				phandle = <0x7e>;
			};

			blsp2-uart1-2pins {
				pins = "gpio4\0gpio5";
				function = "blsp_uart8";
				drive-strength = <0x10>;
				bias-disable;
				phandle = <0x81>;
			};

			blsp2-uart1-2pins-sleep {
				pins = "gpio4\0gpio5";
				function = "gpio";
				drive-strength = <0x02>;
				bias-disable;
				phandle = <0x82>;
			};

			blsp2-i2c2 {
				pins = "gpio6\0gpio7";
				function = "blsp_i2c8";
				drive-strength = <0x10>;
				bias-disable;
				phandle = <0x88>;
			};

			blsp2-i2c2-sleep {
				pins = "gpio6\0gpio7";
				function = "gpio";
				drive-strength = <0x02>;
				bias-disable;
				phandle = <0x89>;
			};

			cci0-default {
				pins = "gpio17\0gpio18";
				function = "cci_i2c";
				drive-strength = <0x10>;
				bias-disable;
				phandle = <0x49>;
			};

			camera-rear-default {
				phandle = <0xd6>;

				mclk0 {
					pins = "gpio13";
					function = "cam_mclk";
					drive-strength = <0x10>;
					bias-disable;
					phandle = <0xd7>;
				};

				rst {
					pins = "gpio25";
					function = "gpio";
					drive-strength = <0x10>;
					bias-disable;
					phandle = <0xd8>;
				};

				pwdn {
					pins = "gpio26";
					function = "gpio";
					drive-strength = <0x10>;
					bias-disable;
					phandle = <0xd9>;
				};
			};

			cci1-default {
				pins = "gpio19\0gpio20";
				function = "cci_i2c";
				drive-strength = <0x10>;
				bias-disable;
				phandle = <0x4a>;
			};

			camera-board-default {
				phandle = <0xda>;

				mclk1 {
					pins = "gpio14";
					function = "cam_mclk";
					drive-strength = <0x10>;
					bias-disable;
				};

				pwdn {
					pins = "gpio98";
					function = "gpio";
					drive-strength = <0x10>;
					bias-disable;
				};

				rst {
					pins = "gpio104";
					function = "gpio";
					drive-strength = <0x10>;
					bias-disable;
				};
			};

			camera-front-default {
				phandle = <0xdb>;

				mclk2 {
					pins = "gpio15";
					function = "cam_mclk";
					drive-strength = <0x10>;
					bias-disable;
					phandle = <0xdc>;
				};

				rst {
					pins = "gpio23";
					function = "gpio";
					drive-strength = <0x10>;
					bias-disable;
					phandle = <0xdd>;
				};

				pwdn {
					pins = "gpio133";
					function = "gpio";
					drive-strength = <0x10>;
					bias-disable;
				};
			};

			pcie0-state-on {
				phandle = <0x3a>;

				perst {
					pins = "gpio35";
					function = "gpio";
					drive-strength = <0x02>;
					bias-pull-down;
				};

				clkreq {
					pins = "gpio36";
					function = "pci_e0";
					drive-strength = <0x02>;
					bias-pull-up;
				};

				wake {
					pins = "gpio37";
					function = "gpio";
					drive-strength = <0x02>;
					bias-pull-up;
				};
			};

			pcie0-state-off {
				phandle = <0x3b>;

				perst {
					pins = "gpio35";
					function = "gpio";
					drive-strength = <0x02>;
					bias-pull-down;
				};

				clkreq {
					pins = "gpio36";
					function = "gpio";
					drive-strength = <0x02>;
					bias-disable;
				};

				wake {
					pins = "gpio37";
					function = "gpio";
					drive-strength = <0x02>;
					bias-disable;
				};
			};

			blsp1-i2c2-default {
				pins = "gpio47\0gpio48";
				function = "blsp_i2c3";
				drive-strength = <0x10>;
				bias-disable = <0x00>;
				phandle = <0x7f>;
			};

			blsp1-i2c2-sleep {
				pins = "gpio47\0gpio48";
				function = "gpio";
				drive-strength = <0x02>;
				bias-disable = <0x00>;
				phandle = <0x80>;
			};

			blsp2-uart2-4pins {
				pins = "gpio49\0gpio50\0gpio51\0gpio52";
				function = "blsp_uart9";
				drive-strength = <0x10>;
				bias-disable;
				phandle = <0x83>;
			};

			blsp2-uart2-4pins-sleep {
				pins = "gpio49\0gpio50\0gpio51\0gpio52";
				function = "blsp_uart9";
				drive-strength = <0x02>;
				bias-disable;
				phandle = <0x84>;
			};

			wcd-intr-default {
				pins = "gpio54";
				function = "gpio";
				drive-strength = <0x02>;
				bias-pull-down;
				input-enable;
				phandle = <0x93>;
			};

			blsp2-i2c1 {
				pins = "gpio55\0gpio56";
				function = "blsp_i2c7";
				drive-strength = <0x10>;
				bias-disable;
				phandle = <0x85>;
			};

			blsp2-i2c0-sleep {
				pins = "gpio55\0gpio56";
				function = "gpio";
				drive-strength = <0x02>;
				bias-disable;
				phandle = <0x86>;
			};

			blsp2-i2c5 {
				pins = "gpio60\0gpio61";
				function = "blsp_i2c11";
				drive-strength = <0x02>;
				bias-disable;
				phandle = <0x8a>;
			};

			cdc-reset-active {
				pins = "gpio64";
				function = "gpio";
				drive-strength = <0x10>;
				bias-pull-down;
				output-high;
				phandle = <0x92>;
			};

			cdc-reset-sleep {
				pins = "gpio64";
				function = "gpio";
				drive-strength = <0x10>;
				bias-disable;
				output-low;
				phandle = <0xde>;
			};

			blsp2-spi5-default {
				phandle = <0x8d>;

				spi {
					pins = "gpio85\0gpio86\0gpio88";
					function = "blsp_spi12";
					drive-strength = <0x0c>;
					bias-disable;
				};

				cs {
					pins = "gpio87";
					function = "gpio";
					drive-strength = <0x10>;
					bias-disable;
					output-high;
				};
			};

			blsp2-spi5-sleep {
				pins = "gpio85\0gpio86\0gpio87\0gpio88";
				function = "gpio";
				drive-strength = <0x02>;
				bias-pull-down;
				phandle = <0x8e>;
			};

			blsp2-i2c6 {
				pins = "gpio87\0gpio88";
				function = "blsp_i2c12";
				drive-strength = <0x10>;
				bias-disable;
				phandle = <0x8b>;
			};

			blsp2-i2c6-sleep {
				pins = "gpio87\0gpio88";
				function = "gpio";
				drive-strength = <0x02>;
				bias-disable;
				phandle = <0x8c>;
			};

			pcie1-state-on {
				phandle = <0x3e>;

				perst {
					pins = "gpio130";
					function = "gpio";
					drive-strength = <0x02>;
					bias-pull-down;
				};

				clkreq {
					pins = "gpio131";
					function = "pci_e1";
					drive-strength = <0x02>;
					bias-pull-up;
				};

				wake {
					pins = "gpio132";
					function = "gpio";
					drive-strength = <0x02>;
					bias-pull-down;
				};
			};

			pcie1-state-off {
				phandle = <0x3f>;

				clkreq {
					pins = "gpio131";
					function = "gpio";
					drive-strength = <0x02>;
					bias-disable;
				};

				wake {
					pins = "gpio132";
					function = "gpio";
					drive-strength = <0x02>;
					bias-disable;
				};
			};

			pcie2-state-on {
				phandle = <0x41>;

				perst {
					pins = "gpio114";
					function = "gpio";
					drive-strength = <0x02>;
					bias-pull-down;
				};

				clkreq {
					pins = "gpio115";
					function = "pci_e2";
					drive-strength = <0x02>;
					bias-pull-up;
				};

				wake {
					pins = "gpio116";
					function = "gpio";
					drive-strength = <0x02>;
					bias-pull-down;
				};
			};

			pcie2-state-off {
				phandle = <0x42>;

				clkreq {
					pins = "gpio115";
					function = "gpio";
					drive-strength = <0x02>;
					bias-disable;
				};

				wake {
					pins = "gpio116";
					function = "gpio";
					drive-strength = <0x02>;
					bias-disable;
				};
			};

			sdc1-state-on {
				phandle = <0x71>;

				clk {
					pins = "sdc1_clk";
					bias-disable;
					drive-strength = <0x10>;
				};

				cmd {
					pins = "sdc1_cmd";
					bias-pull-up;
					drive-strength = <0x0a>;
				};

				data {
					pins = "sdc1_data";
					bias-pull-up;
					drive-strength = <0x0a>;
				};

				rclk {
					pins = "sdc1_rclk";
					bias-pull-down;
				};
			};

			sdc1-state-off {
				phandle = <0x72>;

				clk {
					pins = "sdc1_clk";
					bias-disable;
					drive-strength = <0x02>;
				};

				cmd {
					pins = "sdc1_cmd";
					bias-pull-up;
					drive-strength = <0x02>;
				};

				data {
					pins = "sdc1_data";
					bias-pull-up;
					drive-strength = <0x02>;
				};

				rclk {
					pins = "sdc1_rclk";
					bias-pull-down;
				};
			};

			sdc2-clk-on {
				phandle = <0x73>;

				clk {
					pins = "sdc2_clk";
					bias-disable;
					drive-strength = <0x10>;
				};

				cmd {
					pins = "sdc2_cmd";
					bias-pull-up;
					drive-strength = <0x0a>;
				};

				data {
					pins = "sdc2_data";
					bias-pull-up;
					drive-strength = <0x0a>;
				};
			};

			sdc2-clk-off {
				phandle = <0x75>;

				clk {
					pins = "sdc2_clk";
					bias-disable;
					drive-strength = <0x02>;
				};

				cmd {
					pins = "sdc2_cmd";
					bias-pull-up;
					drive-strength = <0x02>;
				};

				data {
					pins = "sdc2_data";
					bias-pull-up;
					drive-strength = <0x02>;
				};
			};

			sdc2_cd_on {
				phandle = <0x74>;

				mux {
					pins = "gpio38";
					function = "gpio";
				};

				config {
					pins = "gpio38";
					bias-pull-up;
					drive-strength = <0x10>;
				};
			};

			sdc2_cd_off {
				phandle = <0x76>;

				mux {
					pins = "gpio38";
					function = "gpio";
				};

				config {
					pins = "gpio38";
					bias-pull-up;
					drive-strength = <0x02>;
				};
			};

			blsp1_uart2_default {
				phandle = <0x7a>;

				mux {
					pins = "gpio41\0gpio42\0gpio43\0gpio44";
					function = "blsp_uart2";
				};

				config {
					pins = "gpio41\0gpio42\0gpio43\0gpio44";
					drive-strength = <0x10>;
					bias-disable;
				};
			};

			blsp1_uart2_sleep {
				phandle = <0x7b>;

				mux {
					pins = "gpio41\0gpio42\0gpio43\0gpio44";
					function = "gpio";
				};

				config {
					pins = "gpio41\0gpio42\0gpio43\0gpio44";
					drive-strength = <0x02>;
					bias-disable;
				};
			};

			hdmi_hpd_active {
				phandle = <0x2b>;

				mux {
					pins = "gpio34";
					function = "hdmi_hot";
				};

				config {
					pins = "gpio34";
					bias-pull-down;
					drive-strength = <0x10>;
				};
			};

			hdmi_hpd_suspend {
				phandle = <0x2d>;

				mux {
					pins = "gpio34";
					function = "hdmi_hot";
				};

				config {
					pins = "gpio34";
					bias-pull-down;
					drive-strength = <0x02>;
				};
			};

			hdmi_ddc_active {
				phandle = <0x2c>;

				mux {
					pins = "gpio32\0gpio33";
					function = "hdmi_ddc";
				};

				config {
					pins = "gpio32\0gpio33";
					drive-strength = <0x02>;
					bias-pull-up;
				};
			};

			hdmi_ddc_suspend {
				phandle = <0x2e>;

				mux {
					pins = "gpio32\0gpio33";
					function = "hdmi_ddc";
				};

				config {
					pins = "gpio32\0gpio33";
					drive-strength = <0x02>;
					bias-pull-down;
				};
			};
		};

		qcom,spmi@400f000 {
			compatible = "qcom,spmi-pmic-arb";
			reg = <0x400f000 0x1000 0x4400000 0x800000 0x4c00000 0x800000 0x5800000 0x200000 0x400a000 0x2100>;
			reg-names = "core\0chnls\0obsrvr\0intr\0cnfg";
			interrupt-names = "periph_irq";
			interrupts = <0x00 0x146 0x04>;
			qcom,ee = <0x00>;
			qcom,channel = <0x00>;
			#address-cells = <0x02>;
			#size-cells = <0x00>;
			interrupt-controller;
			#interrupt-cells = <0x04>;
			phandle = <0xdf>;

			pmic@0 {
				compatible = "qcom,pm8994\0qcom,spmi-pmic";
				reg = <0x00 0x00>;
				#address-cells = <0x01>;
				#size-cells = <0x00>;

				rtc@6000 {
					compatible = "qcom,pm8941-rtc";
					reg = <0x6000 0x6100>;
					reg-names = "rtc\0alarm";
					interrupts = <0x00 0x61 0x01 0x01>;
				};

				pon@800 {
					compatible = "qcom,pm8916-pon";
					reg = <0x800>;
					mode-bootloader = <0x02>;
					mode-recovery = <0x01>;
					phandle = <0xe0>;

					pwrkey {
						compatible = "qcom,pm8941-pwrkey";
						interrupts = <0x00 0x08 0x00 0x03>;
						debounce = <0x3d09>;
						bias-pull-up;
						linux,code = <0x74>;
					};

					resin {
						compatible = "qcom,pm8941-resin";
						interrupts = <0x00 0x08 0x01 0x03>;
						debounce = <0x3d09>;
						bias-pull-up;
						status = "okay";
						linux,code = <0x72>;
						phandle = <0xe1>;
					};
				};

				temp-alarm@2400 {
					compatible = "qcom,spmi-temp-alarm";
					reg = <0x2400>;
					interrupts = <0x00 0x24 0x00 0x01>;
					io-channels = <0x34 0x08>;
					io-channel-names = "thermal";
					#thermal-sensor-cells = <0x00>;
					phandle = <0xa5>;
				};

				adc@3100 {
					compatible = "qcom,spmi-vadc";
					reg = <0x3100>;
					interrupts = <0x00 0x31 0x00 0x01>;
					#address-cells = <0x01>;
					#size-cells = <0x00>;
					#io-channel-cells = <0x01>;
					phandle = <0x34>;

					adc-chan@7 {
						reg = <0x07>;
						qcom,pre-scaling = <0x01 0x03>;
						label = "vph_pwr";
					};

					adc-chan@8 {
						reg = <0x08>;
						label = "die_temp";
					};

					adc-chan@9 {
						reg = <0x09>;
						label = "ref_625mv";
					};

					adc-chan@a {
						reg = <0x0a>;
						label = "ref_1250mv";
					};

					adc-chan@e {
						reg = <0x0e>;
					};

					adc-chan@f {
						reg = <0x0f>;
					};
				};

				gpios@c000 {
					compatible = "qcom,pm8994-gpio\0qcom,spmi-gpio";
					reg = <0xc000>;
					gpio-controller;
					gpio-ranges = <0x05 0x00 0x00 0x16>;
					#gpio-cells = <0x02>;
					interrupt-controller;
					#interrupt-cells = <0x02>;
					gpio-line-names = "NC\0KEY_VOLP_N\0NC\0BL1_PWM\0GPIO-F\0BL1_EN\0NC\0WLAN_EN\0NC\0NC\0NC\0NC\0NC\0NC\0DIVCLK1\0DIVCLK2\0DIVCLK3\0DIVCLK4\0BT_EN\0PMIC_SLB\0PMIC_BUA\0USB_VBUS_DET";
					pinctrl-names = "default";
					pinctrl-0 = <0x35 0x36>;
					phandle = <0x05>;

					pm8994_gpio5 {
						phandle = <0x35>;

						pinconf {
							pins = "gpio5";
							output-low;
							power-source = <0x02>;
						};
					};

					bt_en_gpios {
						phandle = <0x36>;

						pinconf {
							pins = "gpio19";
							function = "normal";
							output-low;
							power-source = <0x02>;
							qcom,drive-strength = <0x03>;
							bias-pull-down;
						};
					};

					wlan_en_gpios {
						phandle = <0xa9>;

						pinconf {
							pins = "gpio8";
							function = "normal";
							output-low;
							power-source = <0x02>;
							qcom,drive-strength = <0x03>;
							bias-pull-down;
						};
					};

					clk_div1 {
						phandle = <0x03>;

						pinconf {
							pins = "gpio15";
							function = "func1";
							power-source = <0x02>;
						};
					};

					pm8996_gpio2 {
						phandle = <0xa6>;

						pinconf {
							pins = "gpio2";
							function = "normal";
							input-enable;
							drive-push-pull;
							bias-pull-up;
							qcom,drive-strength = <0x00>;
							power-source = <0x02>;
						};
					};

					divclk4 {
						phandle = <0x02>;

						pinconf {
							pins = "gpio18";
							function = "func2";
							bias-disable;
							power-source = <0x02>;
						};
					};

					pm8996_gpio22 {
						phandle = <0xa8>;

						pinconf {
							pins = "gpio22";
							function = "normal";
							input-enable;
							bias-pull-down;
							qcom,drive-strength = <0x00>;
							power-source = <0x02>;
						};
					};
				};

				mpps@a000 {
					compatible = "qcom,pm8994-mpp";
					reg = <0xa000>;
					gpio-controller;
					#gpio-cells = <0x02>;
					interrupts = <0x00 0xa0 0x00 0x00 0x00 0xa1 0x00 0x00 0x00 0xa2 0x00 0x00 0x00 0xa3 0x00 0x00 0x00 0xa4 0x00 0x00 0x00 0xa5 0x00 0x00 0x00 0xa6 0x00 0x00 0x00 0xa7 0x00 0x00>;
					gpio-line-names = "VDDPX_BIAS\0WIFI_LED\0NC\0BT_LED\0PM_MPP05\0PM_MPP06\0PM_MPP07\0NC";
					phandle = <0xe2>;
				};
			};

			pmic@1 {
				compatible = "qcom,pm8994\0qcom,spmi-pmic";
				reg = <0x01 0x00>;
				#address-cells = <0x01>;
				#size-cells = <0x00>;

				regulators {
					compatible = "qcom,pm8994-regulators";
					qcom,saw-reg = <0x37>;
					phandle = <0xe3>;

					s9 {
						qcom,saw-slave;
					};

					s10 {
						qcom,saw-slave;
					};

					s11 {
						qcom,saw-leader;
						regulator-always-on;
						regulator-min-microvolt = <0xef420>;
						regulator-max-microvolt = <0xef420>;
					};
				};
			};

			pmic@2 {
				compatible = "qcom,pmi8994\0qcom,spmi-pmic";
				reg = <0x02 0x00>;
				#address-cells = <0x01>;
				#size-cells = <0x00>;

				gpios@c000 {
					compatible = "qcom,pmi8994-gpio\0qcom,spmi-gpio";
					reg = <0xc000>;
					gpio-controller;
					gpio-ranges = <0x38 0x00 0x00 0x0a>;
					#gpio-cells = <0x02>;
					interrupt-controller;
					#interrupt-cells = <0x02>;
					gpio-line-names = "NC\0SPKR_AMP_EN1\0SPKR_AMP_EN2\0TP61\0NC\0USB2_VBUS_DET\0NC\0NC\0NC\0NC";
					phandle = <0x38>;

					pmi8996_gpio6 {
						phandle = <0xa7>;

						pinconf {
							pins = "gpio6";
							function = "normal";
							input-enable;
							bias-pull-down;
							qcom,drive-strength = <0x00>;
							power-source = <0x02>;
						};
					};
				};
			};

			pmic@3 {
				compatible = "qcom,pmi8994\0qcom,spmi-pmic";
				reg = <0x03 0x00>;
				#address-cells = <0x01>;
				#size-cells = <0x00>;

				regulators {
					compatible = "qcom,pmi8994-regulators";
					#address-cells = <0x01>;
					#size-cells = <0x01>;
					phandle = <0xe4>;

					s2@1700 {
						reg = <0x1700 0x100>;
						regulator-name = "VDD_GFX";
						regulator-min-microvolt = <0xef420>;
						regulator-max-microvolt = <0xef420>;
						phandle = <0x22>;
					};
				};

				wled@d800 {
					compatible = "qcom,pmi8994-wled";
					reg = <0xd800 0xd900>;
					interrupts = <0x03 0xd8 0x02 0x01>;
					interrupt-names = "short";
					qcom,num-strings = <0x03>;
					qcom,enabled-strings = <0x00 0x01 0x02 0x03>;
					qcom,cabc;
					qcom,external-pfet;
					status = "disabled";
					phandle = <0xe5>;
				};
			};
		};

		agnoc@0 {
			power-domains = <0x1e 0x00>;
			compatible = "simple-pm-bus";
			#address-cells = <0x01>;
			#size-cells = <0x01>;
			ranges;

			pcie@600000 {
				compatible = "qcom,pcie-msm8996\0snps,dw-pcie";
				status = "okay";
				power-domains = <0x1e 0x05>;
				bus-range = <0x00 0xff>;
				num-lanes = <0x01>;
				reg = <0x600000 0x2000 0xc000000 0xf1d 0xc000f20 0xa8 0xc100000 0x100000>;
				reg-names = "parf\0dbi\0elbi\0config";
				phys = <0x39>;
				phy-names = "pciephy";
				#address-cells = <0x03>;
				#size-cells = <0x02>;
				ranges = <0x1000000 0x00 0xc200000 0xc200000 0x00 0x100000 0x2000000 0x00 0xc300000 0xc300000 0x00 0xd00000>;
				device_type = "pci";
				interrupts = <0x00 0x195 0x04>;
				interrupt-names = "msi";
				#interrupt-cells = <0x01>;
				interrupt-map-mask = <0x00 0x00 0x00 0x07>;
				interrupt-map = <0x00 0x00 0x00 0x01 0x01 0x00 0xf4 0x04 0x00 0x00 0x00 0x02 0x01 0x00 0xf5 0x04 0x00 0x00 0x00 0x03 0x01 0x00 0xf7 0x04 0x00 0x00 0x00 0x04 0x01 0x00 0xf8 0x04>;
				pinctrl-names = "default\0sleep";
				pinctrl-0 = <0x3a>;
				pinctrl-1 = <0x3b>;
				linux,pci-domain = <0x00>;
				clocks = <0x1e 0xb4 0x1e 0xb3 0x1e 0xb2 0x1e 0xb1 0x1e 0xb0>;
				clock-names = "pipe\0aux\0cfg\0bus_master\0bus_slave";
				perst-gpio = <0x33 0x23 0x01>;
				vddpe-3v3-supply = <0x3c>;
				vdda-supply = <0x1f>;
				phandle = <0xe6>;
			};

			pcie@608000 {
				compatible = "qcom,pcie-msm8996\0snps,dw-pcie";
				power-domains = <0x1e 0x06>;
				bus-range = <0x00 0xff>;
				num-lanes = <0x01>;
				status = "okay";
				reg = <0x608000 0x2000 0xd000000 0xf1d 0xd000f20 0xa8 0xd100000 0x100000>;
				reg-names = "parf\0dbi\0elbi\0config";
				phys = <0x3d>;
				phy-names = "pciephy";
				#address-cells = <0x03>;
				#size-cells = <0x02>;
				ranges = <0x1000000 0x00 0xd200000 0xd200000 0x00 0x100000 0x2000000 0x00 0xd300000 0xd300000 0x00 0xd00000>;
				device_type = "pci";
				interrupts = <0x00 0x19d 0x04>;
				interrupt-names = "msi";
				#interrupt-cells = <0x01>;
				interrupt-map-mask = <0x00 0x00 0x00 0x07>;
				interrupt-map = <0x00 0x00 0x00 0x01 0x01 0x00 0x110 0x04 0x00 0x00 0x00 0x02 0x01 0x00 0x111 0x04 0x00 0x00 0x00 0x03 0x01 0x00 0x112 0x04 0x00 0x00 0x00 0x04 0x01 0x00 0x113 0x04>;
				pinctrl-names = "default\0sleep";
				pinctrl-0 = <0x3e>;
				pinctrl-1 = <0x3f>;
				linux,pci-domain = <0x01>;
				clocks = <0x1e 0xb9 0x1e 0xb8 0x1e 0xb7 0x1e 0xb6 0x1e 0xb5>;
				clock-names = "pipe\0aux\0cfg\0bus_master\0bus_slave";
				perst-gpio = <0x33 0x82 0x01>;
				vdda-supply = <0x1f>;
				phandle = <0xe7>;
			};

			pcie@610000 {
				compatible = "qcom,pcie-msm8996\0snps,dw-pcie";
				power-domains = <0x1e 0x07>;
				bus-range = <0x00 0xff>;
				num-lanes = <0x01>;
				status = "okay";
				reg = <0x610000 0x2000 0xe000000 0xf1d 0xe000f20 0xa8 0xe100000 0x100000>;
				reg-names = "parf\0dbi\0elbi\0config";
				phys = <0x40>;
				phy-names = "pciephy";
				#address-cells = <0x03>;
				#size-cells = <0x02>;
				ranges = <0x1000000 0x00 0xe200000 0xe200000 0x00 0x100000 0x2000000 0x00 0xe300000 0xe300000 0x00 0x1d00000>;
				device_type = "pci";
				interrupts = <0x00 0x1a5 0x04>;
				interrupt-names = "msi";
				#interrupt-cells = <0x01>;
				interrupt-map-mask = <0x00 0x00 0x00 0x07>;
				interrupt-map = <0x00 0x00 0x00 0x01 0x01 0x00 0x8e 0x04 0x00 0x00 0x00 0x02 0x01 0x00 0x8f 0x04 0x00 0x00 0x00 0x03 0x01 0x00 0x90 0x04 0x00 0x00 0x00 0x04 0x01 0x00 0x91 0x04>;
				pinctrl-names = "default\0sleep";
				pinctrl-0 = <0x41>;
				pinctrl-1 = <0x42>;
				linux,pci-domain = <0x02>;
				clocks = <0x1e 0xbe 0x1e 0xbd 0x1e 0xbc 0x1e 0xbb 0x1e 0xba>;
				clock-names = "pipe\0aux\0cfg\0bus_master\0bus_slave";
				perst-gpio = <0x33 0x72 0x01>;
				vdda-supply = <0x1f>;
				phandle = <0xe8>;
			};
		};

		ufshc@624000 {
			compatible = "qcom,ufshc";
			reg = <0x624000 0x2500>;
			interrupts = <0x00 0x109 0x04>;
			phys = <0x43>;
			phy-names = "ufsphy";
			power-domains = <0x1e 0x08>;
			clock-names = "core_clk_src\0core_clk\0bus_clk\0bus_aggr_clk\0iface_clk\0core_clk_unipro_src\0core_clk_unipro\0core_clk_ice\0ref_clk\0tx_lane0_sync_clk\0rx_lane0_sync_clk";
			clocks = <0x1e 0x49 0x1e 0xc1 0x1e 0x52 0x1e 0xd1 0x1e 0xc2 0x1e 0x4a 0x1e 0xc8 0x1e 0xc9 0x04 0x4a 0x1e 0xc5 0x1e 0xc6>;
			freq-table-hz = <0x5f5e100 0xbebc200 0x00 0x00 0x00 0x00 0x00 0x00 0x00 0x00 0x8f0d180 0x11e1a300 0x00 0x00 0x00 0x00 0x00 0x00 0x00 0x00 0x00 0x00>;
			lanes-per-direction = <0x01>;
			#reset-cells = <0x01>;
			status = "okay";
			vcc-supply = <0x44>;
			vccq-supply = <0x45>;
			vccq2-supply = <0x1b>;
			vcc-max-microamp = <0x927c0>;
			vccq-max-microamp = <0x6ddd0>;
			vccq2-max-microamp = <0x6ddd0>;
			phandle = <0x46>;

			ufs_variant {
				compatible = "qcom,ufs_variant";
			};
		};

		phy@627000 {
			compatible = "qcom,msm8996-qmp-ufs-phy";
			reg = <0x627000 0x1c4>;
			#address-cells = <0x01>;
			#size-cells = <0x01>;
			ranges;
			clocks = <0x1e 0xd7>;
			clock-names = "ref";
			resets = <0x46 0x00>;
			reset-names = "ufsphy";
			status = "okay";
			vdda-phy-supply = <0x1f>;
			vdda-pll-supply = <0x20>;
			vddp-ref-clk-supply = <0x45>;
			phandle = <0xe9>;

			phy@627400 {
				reg = <0x627400 0x12c 0x627600 0x200 0x627c00 0x1b4>;
				#phy-cells = <0x00>;
				phandle = <0x43>;
			};
		};

		camss@a00000 {
			compatible = "qcom,msm8996-camss";
			reg = <0xa34000 0x1000 0xa00030 0x04 0xa35000 0x1000 0xa00038 0x04 0xa36000 0x1000 0xa00040 0x04 0xa30000 0x100 0xa30400 0x100 0xa30800 0x100 0xa30c00 0x100 0xa31000 0x500 0xa00020 0x10 0xa10000 0x1000 0xa14000 0x1000>;
			reg-names = "csiphy0\0csiphy0_clk_mux\0csiphy1\0csiphy1_clk_mux\0csiphy2\0csiphy2_clk_mux\0csid0\0csid1\0csid2\0csid3\0ispif\0csi_clk_mux\0vfe0\0vfe1";
			interrupts = <0x00 0x4e 0x01 0x00 0x4f 0x01 0x00 0x50 0x01 0x00 0x128 0x01 0x00 0x129 0x01 0x00 0x12a 0x01 0x00 0x12b 0x01 0x00 0x135 0x01 0x00 0x13a 0x01 0x00 0x13b 0x01>;
			interrupt-names = "csiphy0\0csiphy1\0csiphy2\0csid0\0csid1\0csid2\0csid3\0ispif\0vfe0\0vfe1";
			power-domains = <0x21 0x08 0x21 0x09>;
			clocks = <0x21 0x81 0x21 0xb9 0x21 0x8c 0x21 0x8d 0x21 0x8e 0x21 0xa6 0x21 0xa5 0x21 0xa7 0x21 0xa9 0x21 0xa8 0x21 0xab 0x21 0xaa 0x21 0xac 0x21 0xae 0x21 0xad 0x21 0xb0 0x21 0xaf 0x21 0xb1 0x21 0xb3 0x21 0xb2 0x21 0xb5 0x21 0xb4 0x21 0xb6 0x21 0xb8 0x21 0xb7 0x21 0x82 0x21 0x99 0x21 0x9f 0x21 0x9b 0x21 0x9a 0x21 0x9c 0x21 0xa0 0x21 0x9e 0x21 0x9d 0x21 0x97 0x21 0x98>;
			clock-names = "top_ahb\0ispif_ahb\0csiphy0_timer\0csiphy1_timer\0csiphy2_timer\0csi0_ahb\0csi0\0csi0_phy\0csi0_pix\0csi0_rdi\0csi1_ahb\0csi1\0csi1_phy\0csi1_pix\0csi1_rdi\0csi2_ahb\0csi2\0csi2_phy\0csi2_pix\0csi2_rdi\0csi3_ahb\0csi3\0csi3_phy\0csi3_pix\0csi3_rdi\0ahb\0vfe0\0csi_vfe0\0vfe0_ahb\0vfe0_stream\0vfe1\0csi_vfe1\0vfe1_ahb\0vfe1_stream\0vfe_ahb\0vfe_axi";
			iommus = <0x47 0x00 0x47 0x01 0x47 0x02 0x47 0x03>;
			status = "disabled";
			vdda-supply = <0x48>;
			phandle = <0xea>;

			ports {
				#address-cells = <0x01>;
				#size-cells = <0x00>;
			};
		};

		cci@a0c000 {
			compatible = "qcom,msm8996-cci";
			#address-cells = <0x01>;
			#size-cells = <0x00>;
			reg = <0xa0c000 0x1000>;
			interrupts = <0x00 0x127 0x01>;
			power-domains = <0x21 0x07>;
			clocks = <0x21 0x81 0x21 0x8b 0x21 0x8a 0x21 0x82>;
			clock-names = "camss_top_ahb\0cci_ahb\0cci\0camss_ahb";
			assigned-clocks = <0x21 0x8b 0x21 0x8a>;
			assigned-clock-rates = <0x4c4b400 0x23c3460>;
			pinctrl-names = "default";
			pinctrl-0 = <0x49 0x4a>;
			status = "disabled";
			phandle = <0xeb>;

			i2c-bus@0 {
				reg = <0x00>;
				clock-frequency = <0x61a80>;
				#address-cells = <0x01>;
				#size-cells = <0x00>;
				phandle = <0xec>;
			};

			i2c-bus@1 {
				reg = <0x01>;
				clock-frequency = <0x61a80>;
				#address-cells = <0x01>;
				#size-cells = <0x00>;
				phandle = <0xed>;
			};
		};

		iommu@b40000 {
			compatible = "qcom,msm8996-smmu-v2\0qcom,adreno-smmu\0qcom,smmu-v2";
			reg = <0xb40000 0x10000>;
			#global-interrupts = <0x01>;
			interrupts = <0x00 0x14e 0x04 0x00 0x149 0x04 0x00 0x14a 0x04>;
			#iommu-cells = <0x01>;
			clocks = <0x21 0x68 0x1e 0x5a>;
			clock-names = "iface\0bus";
			power-domains = <0x21 0x03>;
			phandle = <0x30>;
		};

		video-codec@c00000 {
			compatible = "qcom,msm8996-venus";
			reg = <0xc00000 0xff000>;
			interrupts = <0x00 0x11f 0x04>;
			power-domains = <0x21 0x04>;
			clocks = <0x21 0x6e 0x21 0x71 0x21 0x6f 0x21 0x70>;
			clock-names = "core\0iface\0bus\0mbus";
			iommus = <0x4b 0x00 0x4b 0x01 0x4b 0x0a 0x4b 0x07 0x4b 0x0e 0x4b 0x0f 0x4b 0x08 0x4b 0x09 0x4b 0x0b 0x4b 0x0c 0x4b 0x0d 0x4b 0x10 0x4b 0x11 0x4b 0x21 0x4b 0x28 0x4b 0x29 0x4b 0x2b 0x4b 0x2c 0x4b 0x2d 0x4b 0x31>;
			memory-region = <0x4c>;
			status = "okay";
			phandle = <0xee>;

			video-decoder {
				compatible = "venus-decoder";
				clocks = <0x21 0x72>;
				clock-names = "core";
				power-domains = <0x21 0x05>;
			};

			video-encoder {
				compatible = "venus-encoder";
				clocks = <0x21 0x73>;
				clock-names = "core";
				power-domains = <0x21 0x06>;
			};
		};

		iommu@d00000 {
			compatible = "qcom,msm8996-smmu-v2\0qcom,smmu-v2";
			reg = <0xd00000 0x10000>;
			#global-interrupts = <0x01>;
			interrupts = <0x00 0x49 0x04 0x00 0x140 0x04 0x00 0x141 0x04>;
			#iommu-cells = <0x01>;
			clocks = <0x21 0x5b 0x21 0x5c>;
			clock-names = "iface\0bus";
			power-domains = <0x21 0x0d>;
			phandle = <0x24>;
		};

		iommu@d40000 {
			compatible = "qcom,msm8996-smmu-v2\0qcom,smmu-v2";
			reg = <0xd40000 0x20000>;
			#global-interrupts = <0x01>;
			interrupts = <0x00 0x11e 0x04 0x00 0x14f 0x04 0x00 0x150 0x04 0x00 0x151 0x04 0x00 0x152 0x04 0x00 0x153 0x04 0x00 0x154 0x04 0x00 0x155 0x04>;
			power-domains = <0x21 0x00>;
			clocks = <0x21 0x62 0x21 0x63>;
			clock-names = "iface\0bus";
			#iommu-cells = <0x01>;
			status = "okay";
			phandle = <0x4b>;
		};

		iommu@da0000 {
			compatible = "qcom,msm8996-smmu-v2\0qcom,smmu-v2";
			reg = <0xda0000 0x10000>;
			#global-interrupts = <0x01>;
			interrupts = <0x00 0x4c 0x04 0x00 0x157 0x04 0x00 0x158 0x04>;
			power-domains = <0x21 0x02>;
			clocks = <0x21 0x4e 0x21 0x4f>;
			clock-names = "iface\0bus";
			#iommu-cells = <0x01>;
			phandle = <0x47>;
		};

		iommu@1600000 {
			compatible = "qcom,msm8996-smmu-v2\0qcom,smmu-v2";
			reg = <0x1600000 0x20000>;
			#iommu-cells = <0x01>;
			power-domains = <0x1e 0x03>;
			#global-interrupts = <0x01>;
			interrupts = <0x00 0x194 0x04 0x00 0xe2 0x04 0x00 0x189 0x04 0x00 0x18a 0x04 0x00 0x18b 0x04 0x00 0x18c 0x04 0x00 0x18d 0x04 0x00 0x18e 0x04 0x00 0x18f 0x04 0x00 0x190 0x04 0x00 0x191 0x04 0x00 0x192 0x04 0x00 0x193 0x04>;
			clocks = <0x1e 0xdb 0x1e 0xdc>;
			clock-names = "iface\0bus";
			phandle = <0x9a>;
		};

		stm@3002000 {
			compatible = "arm,coresight-stm\0arm,primecell";
			reg = <0x3002000 0x1000 0x8280000 0x180000>;
			reg-names = "stm-base\0stm-stimulus-base";
			clocks = <0x04 0x08 0x04 0x09>;
			clock-names = "apb_pclk\0atclk";

			out-ports {

				port {

					endpoint {
						remote-endpoint = <0x4d>;
						phandle = <0x4f>;
					};
				};
			};
		};

		tpiu@3020000 {
			compatible = "arm,coresight-tpiu\0arm,primecell";
			reg = <0x3020000 0x1000>;
			clocks = <0x04 0x08 0x04 0x09>;
			clock-names = "apb_pclk\0atclk";

			in-ports {

				port {

					endpoint {
						remote-endpoint = <0x4e>;
						phandle = <0x5a>;
					};
				};
			};
		};

		funnel@3021000 {
			compatible = "arm,coresight-dynamic-funnel\0arm,primecell";
			reg = <0x3021000 0x1000>;
			clocks = <0x04 0x08 0x04 0x09>;
			clock-names = "apb_pclk\0atclk";

			in-ports {
				#address-cells = <0x01>;
				#size-cells = <0x00>;

				port@7 {
					reg = <0x07>;

					endpoint {
						remote-endpoint = <0x4f>;
						phandle = <0x4d>;
					};
				};
			};

			out-ports {

				port {

					endpoint {
						remote-endpoint = <0x50>;
						phandle = <0x54>;
					};
				};
			};
		};

		funnel@3022000 {
			compatible = "arm,coresight-dynamic-funnel\0arm,primecell";
			reg = <0x3022000 0x1000>;
			clocks = <0x04 0x08 0x04 0x09>;
			clock-names = "apb_pclk\0atclk";

			in-ports {
				#address-cells = <0x01>;
				#size-cells = <0x00>;

				port@6 {
					reg = <0x06>;

					endpoint {
						remote-endpoint = <0x51>;
						phandle = <0x6a>;
					};
				};
			};

			out-ports {

				port {

					endpoint {
						remote-endpoint = <0x52>;
						phandle = <0x55>;
					};
				};
			};
		};

		funnel@3023000 {
			compatible = "arm,coresight-dynamic-funnel\0arm,primecell";
			reg = <0x3023000 0x1000>;
			clocks = <0x04 0x08 0x04 0x09>;
			clock-names = "apb_pclk\0atclk";

			out-ports {

				port {

					endpoint {
						remote-endpoint = <0x53>;
						phandle = <0x56>;
					};
				};
			};
		};

		funnel@3025000 {
			compatible = "arm,coresight-dynamic-funnel\0arm,primecell";
			reg = <0x3025000 0x1000>;
			clocks = <0x04 0x08 0x04 0x09>;
			clock-names = "apb_pclk\0atclk";

			in-ports {
				#address-cells = <0x01>;
				#size-cells = <0x00>;

				port@0 {
					reg = <0x00>;

					endpoint {
						remote-endpoint = <0x54>;
						phandle = <0x50>;
					};
				};

				port@1 {
					reg = <0x01>;

					endpoint {
						remote-endpoint = <0x55>;
						phandle = <0x52>;
					};
				};

				port@2 {
					reg = <0x02>;

					endpoint {
						remote-endpoint = <0x56>;
						phandle = <0x53>;
					};
				};
			};

			out-ports {

				port {

					endpoint {
						remote-endpoint = <0x57>;
						phandle = <0x5b>;
					};
				};
			};
		};

		replicator@3026000 {
			compatible = "arm,coresight-dynamic-replicator\0arm,primecell";
			reg = <0x3026000 0x1000>;
			clocks = <0x04 0x08 0x04 0x09>;
			clock-names = "apb_pclk\0atclk";

			in-ports {

				port {

					endpoint {
						remote-endpoint = <0x58>;
						phandle = <0x5c>;
					};
				};
			};

			out-ports {
				#address-cells = <0x01>;
				#size-cells = <0x00>;

				port@0 {
					reg = <0x00>;

					endpoint {
						remote-endpoint = <0x59>;
						phandle = <0x5d>;
					};
				};

				port@1 {
					reg = <0x01>;

					endpoint {
						remote-endpoint = <0x5a>;
						phandle = <0x4e>;
					};
				};
			};
		};

		etf@3027000 {
			compatible = "arm,coresight-tmc\0arm,primecell";
			reg = <0x3027000 0x1000>;
			clocks = <0x04 0x08 0x04 0x09>;
			clock-names = "apb_pclk\0atclk";

			in-ports {

				port {

					endpoint {
						remote-endpoint = <0x5b>;
						phandle = <0x57>;
					};
				};
			};

			out-ports {

				port {

					endpoint {
						remote-endpoint = <0x5c>;
						phandle = <0x58>;
					};
				};
			};
		};

		etr@3028000 {
			compatible = "arm,coresight-tmc\0arm,primecell";
			reg = <0x3028000 0x1000>;
			clocks = <0x04 0x08 0x04 0x09>;
			clock-names = "apb_pclk\0atclk";
			arm,scatter-gather;

			in-ports {

				port {

					endpoint {
						remote-endpoint = <0x5d>;
						phandle = <0x59>;
					};
				};
			};
		};

		debug@3810000 {
			compatible = "arm,coresight-cpu-debug\0arm,primecell";
			reg = <0x3810000 0x1000>;
			clocks = <0x04 0x08>;
			clock-names = "apb_pclk";
			cpu = <0x0c>;
		};

		etm@3840000 {
			compatible = "arm,coresight-etm4x\0arm,primecell";
			reg = <0x3840000 0x1000>;
			clocks = <0x04 0x08 0x04 0x09>;
			clock-names = "apb_pclk\0atclk";
			cpu = <0x0c>;

			out-ports {

				port {

					endpoint {
						remote-endpoint = <0x5e>;
						phandle = <0x60>;
					};
				};
			};
		};

		debug@3910000 {
			compatible = "arm,coresight-cpu-debug\0arm,primecell";
			reg = <0x3910000 0x1000>;
			clocks = <0x04 0x08>;
			clock-names = "apb_pclk";
			cpu = <0x0d>;
		};

		etm@3940000 {
			compatible = "arm,coresight-etm4x\0arm,primecell";
			reg = <0x3940000 0x1000>;
			clocks = <0x04 0x08 0x04 0x09>;
			clock-names = "apb_pclk\0atclk";
			cpu = <0x0d>;

			out-ports {

				port {

					endpoint {
						remote-endpoint = <0x5f>;
						phandle = <0x61>;
					};
				};
			};
		};

		funnel@39b0000 {
			compatible = "arm,coresight-dynamic-funnel\0arm,primecell";
			reg = <0x39b0000 0x1000>;
			clocks = <0x04 0x08 0x04 0x09>;
			clock-names = "apb_pclk\0atclk";

			in-ports {
				#address-cells = <0x01>;
				#size-cells = <0x00>;

				port@0 {
					reg = <0x00>;

					endpoint {
						remote-endpoint = <0x60>;
						phandle = <0x5e>;
					};
				};

				port@1 {
					reg = <0x01>;

					endpoint {
						remote-endpoint = <0x61>;
						phandle = <0x5f>;
					};
				};
			};

			out-ports {

				port {

					endpoint {
						remote-endpoint = <0x62>;
						phandle = <0x68>;
					};
				};
			};
		};

		debug@3a10000 {
			compatible = "arm,coresight-cpu-debug\0arm,primecell";
			reg = <0x3a10000 0x1000>;
			clocks = <0x04 0x08>;
			clock-names = "apb_pclk";
			cpu = <0x0e>;
		};

		etm@3a40000 {
			compatible = "arm,coresight-etm4x\0arm,primecell";
			reg = <0x3a40000 0x1000>;
			clocks = <0x04 0x08 0x04 0x09>;
			clock-names = "apb_pclk\0atclk";
			cpu = <0x0e>;

			out-ports {

				port {

					endpoint {
						remote-endpoint = <0x63>;
						phandle = <0x65>;
					};
				};
			};
		};

		debug@3b10000 {
			compatible = "arm,coresight-cpu-debug\0arm,primecell";
			reg = <0x3b10000 0x1000>;
			clocks = <0x04 0x08>;
			clock-names = "apb_pclk";
			cpu = <0x0f>;
		};

		etm@3b40000 {
			compatible = "arm,coresight-etm4x\0arm,primecell";
			reg = <0x3b40000 0x1000>;
			clocks = <0x04 0x08 0x04 0x09>;
			clock-names = "apb_pclk\0atclk";
			cpu = <0x0f>;

			out-ports {

				port {

					endpoint {
						remote-endpoint = <0x64>;
						phandle = <0x66>;
					};
				};
			};
		};

		funnel@3bb0000 {
			compatible = "arm,coresight-dynamic-funnel\0arm,primecell";
			reg = <0x3bb0000 0x1000>;
			clocks = <0x04 0x08 0x04 0x09>;
			clock-names = "apb_pclk\0atclk";

			in-ports {
				#address-cells = <0x01>;
				#size-cells = <0x00>;

				port@0 {
					reg = <0x00>;

					endpoint {
						remote-endpoint = <0x65>;
						phandle = <0x63>;
					};
				};

				port@1 {
					reg = <0x01>;

					endpoint {
						remote-endpoint = <0x66>;
						phandle = <0x64>;
					};
				};
			};

			out-ports {

				port {

					endpoint {
						remote-endpoint = <0x67>;
						phandle = <0x69>;
					};
				};
			};
		};

		funnel@3bc0000 {
			compatible = "arm,coresight-dynamic-funnel\0arm,primecell";
			reg = <0x3bc0000 0x1000>;
			clocks = <0x04 0x08 0x04 0x09>;
			clock-names = "apb_pclk\0atclk";

			in-ports {
				#address-cells = <0x01>;
				#size-cells = <0x00>;

				port@0 {
					reg = <0x00>;

					endpoint {
						remote-endpoint = <0x68>;
						phandle = <0x62>;
					};
				};

				port@1 {
					reg = <0x01>;

					endpoint {
						remote-endpoint = <0x69>;
						phandle = <0x67>;
					};
				};
			};

			out-ports {

				port {

					endpoint {
						remote-endpoint = <0x6a>;
						phandle = <0x51>;
					};
				};
			};
		};

		clock-controller@6400000 {
			compatible = "qcom,msm8996-apcc";
			reg = <0x6400000 0x90000>;
			clock-names = "xo";
			clocks = <0x29>;
			#clock-cells = <0x01>;
			phandle = <0x07>;
		};

		usb@6af8800 {
			compatible = "qcom,msm8996-dwc3\0qcom,dwc3";
			reg = <0x6af8800 0x400>;
			#address-cells = <0x01>;
			#size-cells = <0x01>;
			ranges;
			interrupts = <0x00 0x15b 0x04 0x00 0xf3 0x04>;
			interrupt-names = "hs_phy_irq\0ss_phy_irq";
			clocks = <0x1e 0x51 0x1e 0x5b 0x1e 0xd2 0x1e 0x5d 0x1e 0x5c 0x1e 0x63>;
			assigned-clocks = <0x1e 0x5d 0x1e 0x5b>;
			assigned-clock-rates = <0x124f800 0x7270e00>;
			power-domains = <0x1e 0x04>;
			status = "okay";
			extcon = <0x6b>;
			phandle = <0xef>;

			dwc3@6a00000 {
				compatible = "snps,dwc3";
				reg = <0x6a00000 0xcc00>;
				interrupts = <0x00 0x83 0x04>;
				phys = <0x6c 0x6d>;
				phy-names = "usb2-phy\0usb3-phy";
				snps,dis_u2_susphy_quirk;
				snps,dis_enblslpm_quirk;
				extcon = <0x6b>;
				dr_mode = "otg";
				phandle = <0xf0>;
			};
		};

		phy@7410000 {
			compatible = "qcom,msm8996-qmp-usb3-phy";
			reg = <0x7410000 0x1c4>;
			#clock-cells = <0x01>;
			#address-cells = <0x01>;
			#size-cells = <0x01>;
			ranges;
			clocks = <0x1e 0x5e 0x1e 0x63 0x1e 0xd5>;
			clock-names = "aux\0cfg_ahb\0ref";
			resets = <0x1e 0x67 0x1e 0x68>;
			reset-names = "phy\0common";
			status = "okay";
			vdda-phy-supply = <0x1f>;
			vdda-pll-supply = <0x20>;
			phandle = <0xf1>;

			phy@7410200 {
				reg = <0x7410200 0x200 0x7410400 0x130 0x7410600 0x1a8>;
				#phy-cells = <0x00>;
				clock-output-names = "usb3_phy_pipe_clk_src";
				clocks = <0x1e 0x5f>;
				clock-names = "pipe0";
				phandle = <0x6d>;
			};
		};

		phy@7411000 {
			compatible = "qcom,msm8996-qusb2-phy";
			reg = <0x7411000 0x180>;
			#phy-cells = <0x00>;
			clocks = <0x1e 0x63 0x1e 0xda>;
			clock-names = "cfg_ahb\0ref";
			resets = <0x1e 0x09>;
			nvmem-cells = <0x6e>;
			status = "okay";
			vdda-pll-supply = <0x20>;
			vdda-phy-dpdm-supply = <0x6f>;
			phandle = <0x6c>;
		};

		phy@7412000 {
			compatible = "qcom,msm8996-qusb2-phy";
			reg = <0x7412000 0x180>;
			#phy-cells = <0x00>;
			clocks = <0x1e 0x63 0x1e 0xd9>;
			clock-names = "cfg_ahb\0ref";
			resets = <0x1e 0x0a>;
			nvmem-cells = <0x70>;
			status = "okay";
			vdda-pll-supply = <0x20>;
			vdda-phy-dpdm-supply = <0x6f>;
			phandle = <0x90>;
		};

		sdhci@7464900 {
			compatible = "qcom,sdhci-msm-v4";
			reg = <0x7464900 0x11c 0x7464000 0x800>;
			reg-names = "hc_mem\0core_mem";
			interrupts = <0x00 0x8d 0x04 0x00 0x86 0x04>;
			interrupt-names = "hc_irq\0pwr_irq";
			clock-names = "iface\0core\0xo";
			clocks = <0x1e 0x65 0x1e 0x64 0x29>;
			pinctrl-names = "default\0sleep";
			pinctrl-0 = <0x71>;
			pinctrl-1 = <0x72>;
			bus-width = <0x08>;
			non-removable;
			status = "disabled";
			phandle = <0xf2>;
		};

		sdhci@74a4900 {
			compatible = "qcom,sdhci-msm-v4";
			reg = <0x74a4900 0x314 0x74a4000 0x800>;
			reg-names = "hc_mem\0core_mem";
			interrupts = <0x00 0x7d 0x04 0x00 0xdd 0x04>;
			interrupt-names = "hc_irq\0pwr_irq";
			clock-names = "iface\0core\0xo";
			clocks = <0x1e 0x68 0x1e 0x67 0x29>;
			pinctrl-names = "default\0sleep";
			pinctrl-0 = <0x73 0x74>;
			pinctrl-1 = <0x75 0x76>;
			bus-width = <0x04>;
			status = "okay";
			cd-gpios = <0x33 0x26 0x01>;
			vmmc-supply = <0x77>;
			vqmmc-supply = <0x78>;
			phandle = <0xf3>;
		};

		dma@7544000 {
			compatible = "qcom,bam-v1.7.0";
			reg = <0x7544000 0x2b000>;
			interrupts = <0x00 0xee 0x04>;
			clocks = <0x1e 0x6d>;
			clock-names = "bam_clk";
			qcom,controlled-remotely;
			#dma-cells = <0x01>;
			qcom,ee = <0x00>;
			phandle = <0x79>;
		};

		serial@7570000 {
			compatible = "qcom,msm-uartdm-v1.4\0qcom,msm-uartdm";
			reg = <0x7570000 0x1000>;
			interrupts = <0x00 0x6c 0x04>;
			clocks = <0x1e 0x74 0x1e 0x6d>;
			clock-names = "core\0iface";
			dmas = <0x79 0x02 0x79 0x03>;
			dma-names = "tx\0rx";
			status = "okay";
			label = "BT-UART";
			pinctrl-names = "default\0sleep";
			pinctrl-0 = <0x7a>;
			pinctrl-1 = <0x7b>;
			phandle = <0xf4>;

			bluetooth {
				compatible = "qcom,qca6174-bt";
				enable-gpios = <0x05 0x13 0x00>;
				clocks = <0x7c>;
			};
		};

		spi@7575000 {
			compatible = "qcom,spi-qup-v2.2.1";
			reg = <0x7575000 0x600>;
			interrupts = <0x00 0x5f 0x04>;
			clocks = <0x1e 0x6f 0x1e 0x6d>;
			clock-names = "core\0iface";
			pinctrl-names = "default\0sleep";
			pinctrl-0 = <0x7d>;
			pinctrl-1 = <0x7e>;
			dmas = <0x79 0x0c 0x79 0x0d>;
			dma-names = "tx\0rx";
			#address-cells = <0x01>;
			#size-cells = <0x00>;
			status = "okay";
			label = "LS-SPI0";
			phandle = <0xf5>;
		};

		i2c@7577000 {
			compatible = "qcom,i2c-qup-v2.2.1";
			reg = <0x7577000 0x1000>;
			interrupts = <0x00 0x61 0x04>;
			clocks = <0x1e 0x6d 0x1e 0x76>;
			clock-names = "iface\0core";
			pinctrl-names = "default\0sleep";
			pinctrl-0 = <0x7f>;
			pinctrl-1 = <0x80>;
			dmas = <0x79 0x10 0x79 0x11>;
			dma-names = "tx\0rx";
			#address-cells = <0x01>;
			#size-cells = <0x00>;
			status = "okay";
			label = "LS-I2C0";
			phandle = <0xf6>;
		};

		dma@7584000 {
			compatible = "qcom,bam-v1.7.0";
			reg = <0x7584000 0x2b000>;
			interrupts = <0x00 0xef 0x04>;
			clocks = <0x1e 0x81>;
			clock-names = "bam_clk";
			qcom,controlled-remotely;
			#dma-cells = <0x01>;
			qcom,ee = <0x00>;
			phandle = <0x87>;
		};

		serial@75b0000 {
			compatible = "qcom,msm-uartdm-v1.4\0qcom,msm-uartdm";
			reg = <0x75b0000 0x1000>;
			interrupts = <0x00 0x72 0x04>;
			clocks = <0x1e 0x88 0x1e 0x81>;
			clock-names = "core\0iface";
			status = "okay";
			label = "LS-UART1";
			pinctrl-names = "default\0sleep";
			pinctrl-0 = <0x81>;
			pinctrl-1 = <0x82>;
			phandle = <0xf7>;
		};

		serial@75b1000 {
			compatible = "qcom,msm-uartdm-v1.4\0qcom,msm-uartdm";
			reg = <0x75b1000 0x1000>;
			interrupts = <0x00 0x73 0x04>;
			clocks = <0x1e 0x8b 0x1e 0x81>;
			clock-names = "core\0iface";
			status = "disabled";
			label = "LS-UART0";
			pinctrl-names = "default\0sleep";
			pinctrl-0 = <0x83>;
			pinctrl-1 = <0x84>;
			phandle = <0xf8>;
		};

		i2c@75b5000 {
			compatible = "qcom,i2c-qup-v2.2.1";
			reg = <0x75b5000 0x1000>;
			interrupts = <0x00 0x65 0x04>;
			clocks = <0x1e 0x81 0x1e 0x84>;
			clock-names = "iface\0core";
			pinctrl-names = "default\0sleep";
			pinctrl-0 = <0x85>;
			pinctrl-1 = <0x86>;
			dmas = <0x87 0x0c 0x87 0x0d>;
			dma-names = "tx\0rx";
			#address-cells = <0x01>;
			#size-cells = <0x00>;
			status = "okay";
			label = "LS-I2C1";
			phandle = <0xf9>;
		};

		i2c@75b6000 {
			compatible = "qcom,i2c-qup-v2.2.1";
			reg = <0x75b6000 0x1000>;
			interrupts = <0x00 0x66 0x04>;
			clocks = <0x1e 0x81 0x1e 0x87>;
			clock-names = "iface\0core";
			pinctrl-names = "default\0sleep";
			pinctrl-0 = <0x88>;
			pinctrl-1 = <0x89>;
			dmas = <0x87 0x0e 0x87 0x0f>;
			dma-names = "tx\0rx";
			#address-cells = <0x01>;
			#size-cells = <0x00>;
			status = "disabled";
			phandle = <0xfa>;
		};

		i2c@75b9000 {
			compatible = "qcom,i2c-qup-v2.2.1";
			reg = <0x75b9000 0x1000>;
			interrupts = <0x00 0x69 0x04>;
			clocks = <0x1e 0x81 0x1e 0x90>;
			clock-names = "iface\0core";
			pinctrl-names = "default";
			pinctrl-0 = <0x8a>;
			dmas = <0x87 0x14 0x87 0x15>;
			dma-names = "tx\0rx";
			#address-cells = <0x01>;
			#size-cells = <0x00>;
			status = "disabled";
			phandle = <0xfb>;
		};

		i2c@75ba000 {
			compatible = "qcom,i2c-qup-v2.2.1";
			reg = <0x75ba000 0x1000>;
			interrupts = <0x00 0x6a 0x04>;
			clocks = <0x1e 0x81 0x1e 0x93>;
			clock-names = "iface\0core";
			pinctrl-names = "default\0sleep";
			pinctrl-0 = <0x8b>;
			pinctrl-1 = <0x8c>;
			dmas = <0x87 0x16 0x87 0x17>;
			dma-names = "tx\0rx";
			#address-cells = <0x01>;
			#size-cells = <0x00>;
			status = "disabled";
			phandle = <0xfc>;
		};

		spi@75ba000 {
			compatible = "qcom,spi-qup-v2.2.1";
			reg = <0x75ba000 0x600>;
			interrupts = <0x00 0x6a 0x04>;
			clocks = <0x1e 0x92 0x1e 0x81>;
			clock-names = "core\0iface";
			pinctrl-names = "default\0sleep";
			pinctrl-0 = <0x8d>;
			pinctrl-1 = <0x8e>;
			dmas = <0x87 0x16 0x87 0x17>;
			dma-names = "tx\0rx";
			#address-cells = <0x01>;
			#size-cells = <0x00>;
			status = "okay";
			label = "HS-SPI1";
			phandle = <0xfd>;
		};

		usb@76f8800 {
			compatible = "qcom,msm8996-dwc3\0qcom,dwc3";
			reg = <0x76f8800 0x400>;
			#address-cells = <0x01>;
			#size-cells = <0x01>;
			ranges;
			clocks = <0x1e 0x55 0x1e 0x60 0x1e 0x62 0x1e 0x61 0x1e 0x63>;
			assigned-clocks = <0x1e 0x62 0x1e 0x60>;
			assigned-clock-rates = <0x124f800 0x3938700>;
			power-domains = <0x1e 0x04>;
			qcom,select-utmi-as-pipe-clk;
			status = "okay";
			extcon = <0x8f>;
			phandle = <0xfe>;

			dwc3@7600000 {
				compatible = "snps,dwc3";
				reg = <0x7600000 0xcc00>;
				interrupts = <0x00 0x8a 0x04>;
				phys = <0x90>;
				phy-names = "usb2-phy";
				maximum-speed = "high-speed";
				snps,dis_u2_susphy_quirk;
				snps,dis_enblslpm_quirk;
				extcon = <0x8f>;
				dr_mode = "otg";
			};
		};

		dma-controller@9184000 {
			compatible = "qcom,bam-v1.7.0";
			qcom,controlled-remotely;
			reg = <0x9184000 0x32000>;
			num-channels = <0x1f>;
			interrupts = <0x00 0xa4 0x04>;
			#dma-cells = <0x01>;
			qcom,ee = <0x01>;
			qcom,num-ees = <0x02>;
			phandle = <0x91>;
		};

		slim@91c0000 {
			compatible = "qcom,slim-ngd-v1.5.0";
			reg = <0x91c0000 0x2c000>;
			reg-names = "ctrl";
			interrupts = <0x00 0xa3 0x04>;
			dmas = <0x91 0x03 0x91 0x04 0x91 0x05 0x91 0x06>;
			dma-names = "rx\0tx\0tx2\0rx2";
			#address-cells = <0x01>;
			#size-cells = <0x00>;
			phandle = <0xff>;

			ngd@1 {
				reg = <0x01>;
				#address-cells = <0x01>;
				#size-cells = <0x01>;

				tas-ifd {
					compatible = "slim217,1a0";
					reg = <0x00 0x00>;
					phandle = <0x94>;
				};

				codec@1 {
					pinctrl-0 = <0x92 0x93>;
					pinctrl-names = "default";
					compatible = "slim217,1a0";
					reg = <0x01 0x00>;
					interrupt-parent = <0x33>;
					interrupts = <0x36 0x04 0x35 0x04>;
					interrupt-names = "intr1\0intr2";
					interrupt-controller;
					#interrupt-cells = <0x01>;
					reset-gpios = <0x33 0x40 0x00>;
					slim-ifc-dev = <0x94>;
					#sound-dai-cells = <0x01>;
					clock-names = "mclk\0slimbus";
					clocks = <0x95 0x04 0x0a>;
					vdd-buck-supply = <0x1b>;
					vdd-buck-sido-supply = <0x1b>;
					vdd-tx-supply = <0x1b>;
					vdd-rx-supply = <0x1b>;
					vdd-io-supply = <0x1b>;
					phandle = <0x9f>;
				};
			};
		};

		remoteproc@9300000 {
			compatible = "qcom,msm8996-adsp-pil";
			reg = <0x9300000 0x80000>;
			interrupts-extended = <0x01 0x00 0xa2 0x01 0x96 0x00 0x01 0x96 0x01 0x01 0x96 0x02 0x01 0x96 0x03 0x01>;
			interrupt-names = "wdog\0fatal\0ready\0handover\0stop-ack";
			clocks = <0x29>;
			clock-names = "xo";
			memory-region = <0x97>;
			qcom,smem-states = <0x98 0x00>;
			qcom,smem-state-names = "stop";
			power-domains = <0x99 0x00>;
			power-domain-names = "cx";
			status = "okay";
			phandle = <0x100>;

			smd-edge {
				interrupts = <0x00 0x9c 0x01>;
				label = "lpass";
				mboxes = <0x14 0x08>;
				qcom,smd-edge = <0x01>;
				qcom,remote-pid = <0x02>;
				#address-cells = <0x01>;
				#size-cells = <0x00>;

				apr {
					power-domains = <0x1e 0x02>;
					compatible = "qcom,apr-v2";
					qcom,smd-channels = "apr_audio_svc";
					qcom,apr-domain = <0x04>;
					#address-cells = <0x01>;
					#size-cells = <0x00>;

					q6core {
						reg = <0x03>;
						compatible = "qcom,q6core";
					};

					q6afe {
						compatible = "qcom,q6afe";
						reg = <0x04>;
						phandle = <0x101>;

						dais {
							compatible = "qcom,q6afe-dais";
							#address-cells = <0x01>;
							#size-cells = <0x00>;
							#sound-dai-cells = <0x01>;
							phandle = <0x9c>;

							hdmi@1 {
								reg = <0x01>;
							};
						};
					};

					q6asm {
						compatible = "qcom,q6asm";
						reg = <0x07>;
						phandle = <0x102>;

						dais {
							compatible = "qcom,q6asm-dais";
							#address-cells = <0x01>;
							#size-cells = <0x00>;
							#sound-dai-cells = <0x01>;
							iommus = <0x9a 0x01>;
							phandle = <0x9b>;

							dai@0 {
								reg = <0x00>;
							};

							dai@1 {
								reg = <0x01>;
							};

							dai@2 {
								reg = <0x02>;
							};
						};
					};

					q6adm {
						compatible = "qcom,q6adm";
						reg = <0x08>;
						phandle = <0x103>;

						routing {
							compatible = "qcom,q6adm-routing";
							#sound-dai-cells = <0x00>;
							phandle = <0x9d>;
						};
					};
				};
			};
		};

		mailbox@9820000 {
			compatible = "qcom,msm8996-apcs-hmss-global";
			reg = <0x9820000 0x1000>;
			#mbox-cells = <0x01>;
			phandle = <0x14>;
		};

		timer@9840000 {
			#address-cells = <0x01>;
			#size-cells = <0x01>;
			ranges;
			compatible = "arm,armv7-timer-mem";
			reg = <0x9840000 0x1000>;
			clock-frequency = <0x124f800>;

			frame@9850000 {
				frame-number = <0x00>;
				interrupts = <0x00 0x1f 0x04 0x00 0x1e 0x04>;
				reg = <0x9850000 0x1000 0x9860000 0x1000>;
			};

			frame@9870000 {
				frame-number = <0x01>;
				interrupts = <0x00 0x20 0x04>;
				reg = <0x9870000 0x1000>;
				status = "disabled";
			};

			frame@9880000 {
				frame-number = <0x02>;
				interrupts = <0x00 0x21 0x04>;
				reg = <0x9880000 0x1000>;
				status = "disabled";
			};

			frame@9890000 {
				frame-number = <0x03>;
				interrupts = <0x00 0x22 0x04>;
				reg = <0x9890000 0x1000>;
				status = "disabled";
			};

			frame@98a0000 {
				frame-number = <0x04>;
				interrupts = <0x00 0x23 0x04>;
				reg = <0x98a0000 0x1000>;
				status = "disabled";
			};

			frame@98b0000 {
				frame-number = <0x05>;
				interrupts = <0x00 0x24 0x04>;
				reg = <0x98b0000 0x1000>;
				status = "disabled";
			};

			frame@98c0000 {
				frame-number = <0x06>;
				interrupts = <0x00 0x25 0x04>;
				reg = <0x98c0000 0x1000>;
				status = "disabled";
			};
		};

		syscon@9a10000 {
			compatible = "syscon";
			reg = <0x9a10000 0x1000>;
			phandle = <0x37>;
		};

		interrupt-controller@9bc0000 {
			compatible = "qcom,msm8996-gic-v3\0arm,gic-v3";
			#interrupt-cells = <0x03>;
			interrupt-controller;
			#redistributor-regions = <0x01>;
			redistributor-stride = <0x00 0x40000>;
			reg = <0x9bc0000 0x10000 0x9c00000 0x100000>;
			interrupts = <0x01 0x09 0x04>;
			phandle = <0x01>;
		};
	};

	sound {
		compatible = "qcom,apq8096-sndcard";
		model = "DB820c";
		audio-routing = "RX_BIAS\0MCLK\0MM_DL1\0MultiMedia1 Playback\0MM_DL2\0MultiMedia2 Playback\0MultiMedia3 Capture\0MM_UL3";
		phandle = <0x104>;

		mm1-dai-link {
			link-name = "MultiMedia1";

			cpu {
				sound-dai = <0x9b 0x00>;
			};
		};

		mm2-dai-link {
			link-name = "MultiMedia2";

			cpu {
				sound-dai = <0x9b 0x01>;
			};
		};

		mm3-dai-link {
			link-name = "MultiMedia3";

			cpu {
				sound-dai = <0x9b 0x02>;
			};
		};

		hdmi-dai-link {
			link-name = "HDMI";

			cpu {
				sound-dai = <0x9c 0x01>;
			};

			platform {
				sound-dai = <0x9d>;
			};

			codec {
				sound-dai = <0x9e 0x00>;
			};
		};

		slim-dai-link {
			link-name = "SLIM Playback";

			cpu {
				sound-dai = <0x9c 0x0e>;
			};

			platform {
				sound-dai = <0x9d>;
			};

			codec {
				sound-dai = <0x9f 0x06>;
			};
		};

		slimcap-dai-link {
			link-name = "SLIM Capture";

			cpu {
				sound-dai = <0x9c 0x03>;
			};

			platform {
				sound-dai = <0x9d>;
			};

			codec {
				sound-dai = <0x9f 0x01>;
			};
		};
	};

	thermal-zones {

		cpu0-thermal {
			polling-delay-passive = <0xfa>;
			polling-delay = <0x3e8>;
			thermal-sensors = <0xa0 0x03>;

			trips {

				trip-point0 {
					temperature = <0x124f8>;
					hysteresis = <0x7d0>;
					type = "passive";
					phandle = <0x105>;
				};

				cpu_crit {
					temperature = <0x1adb0>;
					hysteresis = <0x7d0>;
					type = "critical";
					phandle = <0x106>;
				};
			};
		};

		cpu1-thermal {
			polling-delay-passive = <0xfa>;
			polling-delay = <0x3e8>;
			thermal-sensors = <0xa0 0x05>;

			trips {

				trip-point0 {
					temperature = <0x124f8>;
					hysteresis = <0x7d0>;
					type = "passive";
					phandle = <0x107>;
				};

				cpu_crit {
					temperature = <0x1adb0>;
					hysteresis = <0x7d0>;
					type = "critical";
					phandle = <0x108>;
				};
			};
		};

		cpu2-thermal {
			polling-delay-passive = <0xfa>;
			polling-delay = <0x3e8>;
			thermal-sensors = <0xa0 0x08>;

			trips {

				trip-point0 {
					temperature = <0x124f8>;
					hysteresis = <0x7d0>;
					type = "passive";
					phandle = <0x109>;
				};

				cpu_crit {
					temperature = <0x1adb0>;
					hysteresis = <0x7d0>;
					type = "critical";
					phandle = <0x10a>;
				};
			};
		};

		cpu3-thermal {
			polling-delay-passive = <0xfa>;
			polling-delay = <0x3e8>;
			thermal-sensors = <0xa0 0x0a>;

			trips {

				trip-point0 {
					temperature = <0x124f8>;
					hysteresis = <0x7d0>;
					type = "passive";
					phandle = <0x10b>;
				};

				cpu_crit {
					temperature = <0x1adb0>;
					hysteresis = <0x7d0>;
					type = "critical";
					phandle = <0x10c>;
				};
			};
		};

		gpu-thermal-top {
			polling-delay-passive = <0xfa>;
			polling-delay = <0x3e8>;
			thermal-sensors = <0xa1 0x06>;

			trips {

				trip-point0 {
					temperature = <0x15f90>;
					hysteresis = <0x7d0>;
					type = "passive";
					phandle = <0xa2>;
				};
			};

			cooling-maps {

				map0 {
					trip = <0xa2>;
					cooling-device = <0xa3 0xffffffff 0xffffffff>;
				};
			};
		};

		gpu-thermal-bottom {
			polling-delay-passive = <0xfa>;
			polling-delay = <0x3e8>;
			thermal-sensors = <0xa1 0x07>;

			trips {

				trip-point0 {
					temperature = <0x15f90>;
					hysteresis = <0x7d0>;
					type = "passive";
					phandle = <0xa4>;
				};
			};

			cooling-maps {

				map0 {
					trip = <0xa4>;
					cooling-device = <0xa3 0xffffffff 0xffffffff>;
				};
			};
		};

		m4m-thermal {
			polling-delay-passive = <0xfa>;
			polling-delay = <0x3e8>;
			thermal-sensors = <0xa0 0x01>;

			trips {

				trip-point0 {
					temperature = <0x15f90>;
					hysteresis = <0x7d0>;
					type = "hot";
					phandle = <0x10d>;
				};
			};
		};

		l3-or-venus-thermal {
			polling-delay-passive = <0xfa>;
			polling-delay = <0x3e8>;
			thermal-sensors = <0xa0 0x02>;

			trips {

				trip-point0 {
					temperature = <0x15f90>;
					hysteresis = <0x7d0>;
					type = "hot";
					phandle = <0x10e>;
				};
			};
		};

		cluster0-l2-thermal {
			polling-delay-passive = <0xfa>;
			polling-delay = <0x3e8>;
			thermal-sensors = <0xa0 0x07>;

			trips {

				trip-point0 {
					temperature = <0x15f90>;
					hysteresis = <0x7d0>;
					type = "hot";
					phandle = <0x10f>;
				};
			};
		};

		cluster1-l2-thermal {
			polling-delay-passive = <0xfa>;
			polling-delay = <0x3e8>;
			thermal-sensors = <0xa0 0x0c>;

			trips {

				trip-point0 {
					temperature = <0x15f90>;
					hysteresis = <0x7d0>;
					type = "hot";
					phandle = <0x110>;
				};
			};
		};

		camera-thermal {
			polling-delay-passive = <0xfa>;
			polling-delay = <0x3e8>;
			thermal-sensors = <0xa1 0x01>;

			trips {

				trip-point0 {
					temperature = <0x15f90>;
					hysteresis = <0x7d0>;
					type = "hot";
					phandle = <0x111>;
				};
			};
		};

		q6-dsp-thermal {
			polling-delay-passive = <0xfa>;
			polling-delay = <0x3e8>;
			thermal-sensors = <0xa1 0x02>;

			trips {

				trip-point0 {
					temperature = <0x15f90>;
					hysteresis = <0x7d0>;
					type = "hot";
					phandle = <0x112>;
				};
			};
		};

		mem-thermal {
			polling-delay-passive = <0xfa>;
			polling-delay = <0x3e8>;
			thermal-sensors = <0xa1 0x03>;

			trips {

				trip-point0 {
					temperature = <0x15f90>;
					hysteresis = <0x7d0>;
					type = "hot";
					phandle = <0x113>;
				};
			};
		};

		modemtx-thermal {
			polling-delay-passive = <0xfa>;
			polling-delay = <0x3e8>;
			thermal-sensors = <0xa1 0x04>;

			trips {

				trip-point0 {
					temperature = <0x15f90>;
					hysteresis = <0x7d0>;
					type = "hot";
					phandle = <0x114>;
				};
			};
		};

		pm8994-thermal {
			polling-delay-passive = <0xfa>;
			polling-delay = <0x3e8>;
			thermal-sensors = <0xa5>;

			trips {

				pm8994-alert0 {
					temperature = <0x17318>;
					hysteresis = <0x7d0>;
					type = "passive";
					phandle = <0x115>;
				};

				pm8994-crit {
					temperature = <0x1e848>;
					hysteresis = <0x7d0>;
					type = "critical";
					phandle = <0x116>;
				};
			};
		};
	};

	timer {
		compatible = "arm,armv8-timer";
		interrupts = <0x01 0x0d 0x08 0x01 0x0e 0x08 0x01 0x0b 0x08 0x01 0x0a 0x08>;
	};

	aliases {
		serial0 = "/soc/serial@75b0000";
		serial1 = "/soc/serial@75b1000";
		serial2 = "/soc/serial@7570000";
		i2c0 = "/soc/i2c@7577000";
		i2c1 = "/soc/i2c@75b5000";
		i2c2 = "/soc/i2c@75b5000";
		spi0 = "/soc/spi@7575000";
		spi1 = "/soc/spi@75ba000";
	};

	gpio_keys {
		compatible = "gpio-keys";
		#address-cells = <0x01>;
		#size-cells = <0x00>;
		autorepeat;
		pinctrl-names = "default";
		pinctrl-0 = <0xa6>;

		button@0 {
			label = "Volume Up";
			linux,code = <0x73>;
			gpios = <0x05 0x02 0x01>;
		};
	};

	usb2-id {
		compatible = "linux,extcon-usb-gpio";
		id-gpio = <0x38 0x06 0x00>;
		pinctrl-names = "default";
		pinctrl-0 = <0xa7>;
		phandle = <0x8f>;
	};

	usb3-id {
		compatible = "linux,extcon-usb-gpio";
		id-gpio = <0x05 0x16 0x00>;
		pinctrl-names = "default";
		pinctrl-0 = <0xa8>;
		phandle = <0x6b>;
	};

	vph-pwr-regulator {
		compatible = "regulator-fixed";
		regulator-name = "vph_pwr";
		regulator-always-on;
		regulator-boot-on;
		regulator-min-microvolt = <0x387520>;
		regulator-max-microvolt = <0x387520>;
		phandle = <0x16>;
	};

	wlan-en-1-8v {
		pinctrl-names = "default";
		pinctrl-0 = <0xa9>;
		compatible = "regulator-fixed";
		regulator-name = "wlan-en-regulator";
		regulator-min-microvolt = <0x1b7740>;
		regulator-max-microvolt = <0x1b7740>;
		gpio = <0x05 0x08 0x00>;
		startup-delay-us = <0x11170>;
		enable-active-high;
		phandle = <0x3c>;
	};

	__symbols__ {
		xo_board = "/clocks/xo-board";
		sleep_clk = "/clocks/sleep-clk";
		divclk4 = "/clocks/divclk4";
		div1_mclk = "/clocks/divclk1";
		CPU0 = "/cpus/cpu@0";
		L2_0 = "/cpus/cpu@0/l2-cache";
		CPU1 = "/cpus/cpu@1";
		CPU2 = "/cpus/cpu@100";
		L2_1 = "/cpus/cpu@100/l2-cache";
		CPU3 = "/cpus/cpu@101";
		CPU_SLEEP_0 = "/cpus/idle-states/cpu-sleep-0";
		cluster0_opp = "/opp_table0";
		cluster1_opp = "/opp_table1";
		tcsr_mutex = "/hwlock";
		mba_region = "/reserved-memory/mba@91500000";
		slpi_region = "/reserved-memory/slpi@90b00000";
		venus_region = "/reserved-memory/venus@90400000";
		adsp_region = "/reserved-memory/adsp@8ea00000";
		mpss_region = "/reserved-memory/mpss@88800000";
		smem_mem = "/reserved-memory/smem-mem@86000000";
		zap_shader_region = "/reserved-memory/gpu@8f200000";
		rpm_requests = "/rpm-glink/rpm-requests";
		rpmcc = "/rpm-glink/rpm-requests/qcom,rpmcc";
		rpmpd = "/rpm-glink/rpm-requests/power-controller";
		rpmpd_opp_table = "/rpm-glink/rpm-requests/power-controller/opp-table";
		rpmpd_opp1 = "/rpm-glink/rpm-requests/power-controller/opp-table/opp1";
		rpmpd_opp2 = "/rpm-glink/rpm-requests/power-controller/opp-table/opp2";
		rpmpd_opp3 = "/rpm-glink/rpm-requests/power-controller/opp-table/opp3";
		rpmpd_opp4 = "/rpm-glink/rpm-requests/power-controller/opp-table/opp4";
		rpmpd_opp5 = "/rpm-glink/rpm-requests/power-controller/opp-table/opp5";
		rpmpd_opp6 = "/rpm-glink/rpm-requests/power-controller/opp-table/opp6";
		vreg_s3a_1p3 = "/rpm-glink/rpm-requests/pm8994-regulators/s3";
		vreg_s4a_1p8 = "/rpm-glink/rpm-requests/pm8994-regulators/s4";
		vreg_s5a_2p15 = "/rpm-glink/rpm-requests/pm8994-regulators/s5";
		vreg_s7a_1p0 = "/rpm-glink/rpm-requests/pm8994-regulators/s7";
		vreg_l1a_1p0 = "/rpm-glink/rpm-requests/pm8994-regulators/l1";
		vreg_l2a_1p25 = "/rpm-glink/rpm-requests/pm8994-regulators/l2";
		vreg_l3a_0p875 = "/rpm-glink/rpm-requests/pm8994-regulators/l3";
		vreg_l4a_1p225 = "/rpm-glink/rpm-requests/pm8994-regulators/l4";
		vreg_l6a_1p2 = "/rpm-glink/rpm-requests/pm8994-regulators/l6";
		vreg_l8a_1p8 = "/rpm-glink/rpm-requests/pm8994-regulators/l8";
		vreg_l9a_1p8 = "/rpm-glink/rpm-requests/pm8994-regulators/l9";
		vreg_l10a_1p8 = "/rpm-glink/rpm-requests/pm8994-regulators/l10";
		vreg_l11a_1p15 = "/rpm-glink/rpm-requests/pm8994-regulators/l11";
		vreg_l12a_1p8 = "/rpm-glink/rpm-requests/pm8994-regulators/l12";
		vreg_l13a_2p95 = "/rpm-glink/rpm-requests/pm8994-regulators/l13";
		vreg_l14a_1p8 = "/rpm-glink/rpm-requests/pm8994-regulators/l14";
		vreg_l15a_1p8 = "/rpm-glink/rpm-requests/pm8994-regulators/l15";
		vreg_l16a_2p7 = "/rpm-glink/rpm-requests/pm8994-regulators/l16";
		vreg_l17a_2p8 = "/rpm-glink/rpm-requests/pm8994-regulators/l17";
		vreg_l18a_2p85 = "/rpm-glink/rpm-requests/pm8994-regulators/l18";
		vreg_l19a_2p8 = "/rpm-glink/rpm-requests/pm8994-regulators/l19";
		vreg_l20a_2p95 = "/rpm-glink/rpm-requests/pm8994-regulators/l20";
		vreg_l21a_2p95 = "/rpm-glink/rpm-requests/pm8994-regulators/l21";
		vreg_l22a_3p0 = "/rpm-glink/rpm-requests/pm8994-regulators/l22";
		vreg_l23a_2p8 = "/rpm-glink/rpm-requests/pm8994-regulators/l23";
		vreg_l24a_3p075 = "/rpm-glink/rpm-requests/pm8994-regulators/l24";
		vreg_l25a_1p2 = "/rpm-glink/rpm-requests/pm8994-regulators/l25";
		vreg_l26a_0p8 = "/rpm-glink/rpm-requests/pm8994-regulators/l27";
		vreg_l28a_0p925 = "/rpm-glink/rpm-requests/pm8994-regulators/l28";
		vreg_l29a_2p8 = "/rpm-glink/rpm-requests/pm8994-regulators/l29";
		vreg_l30a_1p8 = "/rpm-glink/rpm-requests/pm8994-regulators/l30";
		vreg_l32a_1p8 = "/rpm-glink/rpm-requests/pm8994-regulators/l32";
		vreg_lvs1a_1p8 = "/rpm-glink/rpm-requests/pm8994-regulators/lvs1";
		vreg_lvs2a_1p8 = "/rpm-glink/rpm-requests/pm8994-regulators/lvs2";
		vph_pwr_bbyp = "/rpm-glink/rpm-requests/pmi8994-regulators/boost-bypass";
		vreg_s1b_1p025 = "/rpm-glink/rpm-requests/pmi8994-regulators/s1";
		smp2p_adsp_out = "/smp2p-adsp/master-kernel";
		smp2p_adsp_in = "/smp2p-adsp/slave-kernel";
		modem_smp2p_out = "/smp2p-modem/master-kernel";
		modem_smp2p_in = "/smp2p-modem/slave-kernel";
		smp2p_slpi_in = "/smp2p-slpi/slave-kernel";
		smp2p_slpi_out = "/smp2p-slpi/master-kernel";
		soc = "/soc";
		pcie_phy = "/soc/phy@34000";
		pciephy_0 = "/soc/phy@34000/phy@35000";
		pciephy_1 = "/soc/phy@34000/phy@36000";
		pciephy_2 = "/soc/phy@34000/phy@37000";
		rpm_msg_ram = "/soc/sram@68000";
		qusb2p_hstx_trim = "/soc/qfprom@74000/hstx_trim@24e";
		qusb2s_hstx_trim = "/soc/qfprom@74000/hstx_trim@24f";
		speedbin_efuse = "/soc/qfprom@74000/speedbin@133";
		rng = "/soc/rng@83000";
		gcc = "/soc/clock-controller@300000";
		tsens0 = "/soc/thermal-sensor@4a9000";
		tsens1 = "/soc/thermal-sensor@4ad000";
		tcsr_mutex_regs = "/soc/syscon@740000";
		tcsr = "/soc/syscon@7a0000";
		mmcc = "/soc/clock-controller@8c0000";
		mdss = "/soc/mdss@900000";
		mdp = "/soc/mdss@900000/mdp@901000";
		mdp5_intf3_out = "/soc/mdss@900000/mdp@901000/ports/port@0/endpoint";
		mdp5_intf1_out = "/soc/mdss@900000/mdp@901000/ports/port@1/endpoint";
		dsi0 = "/soc/mdss@900000/dsi@994000";
		dsi0_in = "/soc/mdss@900000/dsi@994000/ports/port@0/endpoint";
		dsi0_out = "/soc/mdss@900000/dsi@994000/ports/port@1/endpoint";
		dsi0_phy = "/soc/mdss@900000/dsi-phy@994400";
		hdmi = "/soc/mdss@900000/hdmi-tx@9a0000";
		hdmi_in = "/soc/mdss@900000/hdmi-tx@9a0000/ports/port@0/endpoint";
		hdmi_phy = "/soc/mdss@900000/hdmi-phy@9a0600";
		gpu = "/soc/gpu@b00000";
		gpu_opp_table = "/soc/gpu@b00000/opp-table";
		tlmm = "/soc/pinctrl@1010000";
		blsp1_spi1_default = "/soc/pinctrl@1010000/blsp1-spi1-default";
		blsp1_spi1_sleep = "/soc/pinctrl@1010000/blsp1-spi1-sleep";
		blsp2_uart2_2pins_default = "/soc/pinctrl@1010000/blsp2-uart1-2pins";
		blsp2_uart2_2pins_sleep = "/soc/pinctrl@1010000/blsp2-uart1-2pins-sleep";
		blsp2_i2c2_default = "/soc/pinctrl@1010000/blsp2-i2c2";
		blsp2_i2c2_sleep = "/soc/pinctrl@1010000/blsp2-i2c2-sleep";
		cci0_default = "/soc/pinctrl@1010000/cci0-default";
		camera0_state_on = "/soc/pinctrl@1010000/camera-rear-default";
		camera_rear_default = "/soc/pinctrl@1010000/camera-rear-default";
		camera0_mclk = "/soc/pinctrl@1010000/camera-rear-default/mclk0";
		camera0_rst = "/soc/pinctrl@1010000/camera-rear-default/rst";
		camera0_pwdn = "/soc/pinctrl@1010000/camera-rear-default/pwdn";
		cci1_default = "/soc/pinctrl@1010000/cci1-default";
		camera1_state_on = "/soc/pinctrl@1010000/camera-board-default";
		camera_board_default = "/soc/pinctrl@1010000/camera-board-default";
		camera2_state_on = "/soc/pinctrl@1010000/camera-front-default";
		camera_front_default = "/soc/pinctrl@1010000/camera-front-default";
		camera2_mclk = "/soc/pinctrl@1010000/camera-front-default/mclk2";
		camera2_rst = "/soc/pinctrl@1010000/camera-front-default/rst";
		pcie0_state_on = "/soc/pinctrl@1010000/pcie0-state-on";
		pcie0_state_off = "/soc/pinctrl@1010000/pcie0-state-off";
		blsp1_i2c3_default = "/soc/pinctrl@1010000/blsp1-i2c2-default";
		blsp1_i2c3_sleep = "/soc/pinctrl@1010000/blsp1-i2c2-sleep";
		blsp2_uart3_4pins_default = "/soc/pinctrl@1010000/blsp2-uart2-4pins";
		blsp2_uart3_4pins_sleep = "/soc/pinctrl@1010000/blsp2-uart2-4pins-sleep";
		wcd_intr_default = "/soc/pinctrl@1010000/wcd-intr-default";
		blsp2_i2c1_default = "/soc/pinctrl@1010000/blsp2-i2c1";
		blsp2_i2c1_sleep = "/soc/pinctrl@1010000/blsp2-i2c0-sleep";
		blsp2_i2c5_default = "/soc/pinctrl@1010000/blsp2-i2c5";
		cdc_reset_active = "/soc/pinctrl@1010000/cdc-reset-active";
		cdc_reset_sleep = "/soc/pinctrl@1010000/cdc-reset-sleep";
		blsp2_spi6_default = "/soc/pinctrl@1010000/blsp2-spi5-default";
		blsp2_spi6_sleep = "/soc/pinctrl@1010000/blsp2-spi5-sleep";
		blsp2_i2c6_default = "/soc/pinctrl@1010000/blsp2-i2c6";
		blsp2_i2c6_sleep = "/soc/pinctrl@1010000/blsp2-i2c6-sleep";
		pcie1_state_on = "/soc/pinctrl@1010000/pcie1-state-on";
		pcie1_state_off = "/soc/pinctrl@1010000/pcie1-state-off";
		pcie2_state_on = "/soc/pinctrl@1010000/pcie2-state-on";
		pcie2_state_off = "/soc/pinctrl@1010000/pcie2-state-off";
		sdc1_state_on = "/soc/pinctrl@1010000/sdc1-state-on";
		sdc1_state_off = "/soc/pinctrl@1010000/sdc1-state-off";
		sdc2_state_on = "/soc/pinctrl@1010000/sdc2-clk-on";
		sdc2_state_off = "/soc/pinctrl@1010000/sdc2-clk-off";
		sdc2_cd_on = "/soc/pinctrl@1010000/sdc2_cd_on";
		sdc2_cd_off = "/soc/pinctrl@1010000/sdc2_cd_off";
		blsp1_uart2_default = "/soc/pinctrl@1010000/blsp1_uart2_default";
		blsp1_uart2_sleep = "/soc/pinctrl@1010000/blsp1_uart2_sleep";
		hdmi_hpd_active = "/soc/pinctrl@1010000/hdmi_hpd_active";
		hdmi_hpd_suspend = "/soc/pinctrl@1010000/hdmi_hpd_suspend";
		hdmi_ddc_active = "/soc/pinctrl@1010000/hdmi_ddc_active";
		hdmi_ddc_suspend = "/soc/pinctrl@1010000/hdmi_ddc_suspend";
		spmi_bus = "/soc/qcom,spmi@400f000";
		pm8994_pon = "/soc/qcom,spmi@400f000/pmic@0/pon@800";
		pm8994_resin = "/soc/qcom,spmi@400f000/pmic@0/pon@800/resin";
		pm8994_temp = "/soc/qcom,spmi@400f000/pmic@0/temp-alarm@2400";
		pm8994_vadc = "/soc/qcom,spmi@400f000/pmic@0/adc@3100";
		pm8994_gpios = "/soc/qcom,spmi@400f000/pmic@0/gpios@c000";
		ls_exp_gpio_f = "/soc/qcom,spmi@400f000/pmic@0/gpios@c000/pm8994_gpio5";
		bt_en_gpios = "/soc/qcom,spmi@400f000/pmic@0/gpios@c000/bt_en_gpios";
		wlan_en_gpios = "/soc/qcom,spmi@400f000/pmic@0/gpios@c000/wlan_en_gpios";
		audio_mclk = "/soc/qcom,spmi@400f000/pmic@0/gpios@c000/clk_div1";
		volume_up_gpio = "/soc/qcom,spmi@400f000/pmic@0/gpios@c000/pm8996_gpio2";
		divclk4_pin_a = "/soc/qcom,spmi@400f000/pmic@0/gpios@c000/divclk4";
		usb3_vbus_det_gpio = "/soc/qcom,spmi@400f000/pmic@0/gpios@c000/pm8996_gpio22";
		pm8994_mpps = "/soc/qcom,spmi@400f000/pmic@0/mpps@a000";
		pm8994_spmi_regulators = "/soc/qcom,spmi@400f000/pmic@1/regulators";
		pmi8994_gpios = "/soc/qcom,spmi@400f000/pmic@2/gpios@c000";
		usb2_vbus_det_gpio = "/soc/qcom,spmi@400f000/pmic@2/gpios@c000/pmi8996_gpio6";
		pmi8994_spmi_regulators = "/soc/qcom,spmi@400f000/pmic@3/regulators";
		vdd_gfx = "/soc/qcom,spmi@400f000/pmic@3/regulators/s2@1700";
		pmi8994_wled = "/soc/qcom,spmi@400f000/pmic@3/wled@d800";
		pcie0 = "/soc/agnoc@0/pcie@600000";
		pcie1 = "/soc/agnoc@0/pcie@608000";
		pcie2 = "/soc/agnoc@0/pcie@610000";
		ufshc = "/soc/ufshc@624000";
		ufsphy = "/soc/phy@627000";
		ufsphy_lane = "/soc/phy@627000/phy@627400";
		camss = "/soc/camss@a00000";
		cci = "/soc/cci@a0c000";
		cci_i2c0 = "/soc/cci@a0c000/i2c-bus@0";
		cci_i2c1 = "/soc/cci@a0c000/i2c-bus@1";
		adreno_smmu = "/soc/iommu@b40000";
		venus = "/soc/video-codec@c00000";
		mdp_smmu = "/soc/iommu@d00000";
		venus_smmu = "/soc/iommu@d40000";
		vfe_smmu = "/soc/iommu@da0000";
		lpass_q6_smmu = "/soc/iommu@1600000";
		stm_out = "/soc/stm@3002000/out-ports/port/endpoint";
		tpiu_in = "/soc/tpiu@3020000/in-ports/port/endpoint";
		funnel0_in = "/soc/funnel@3021000/in-ports/port@7/endpoint";
		funnel0_out = "/soc/funnel@3021000/out-ports/port/endpoint";
		funnel1_in = "/soc/funnel@3022000/in-ports/port@6/endpoint";
		funnel1_out = "/soc/funnel@3022000/out-ports/port/endpoint";
		funnel2_out = "/soc/funnel@3023000/out-ports/port/endpoint";
		merge_funnel_in0 = "/soc/funnel@3025000/in-ports/port@0/endpoint";
		merge_funnel_in1 = "/soc/funnel@3025000/in-ports/port@1/endpoint";
		merge_funnel_in2 = "/soc/funnel@3025000/in-ports/port@2/endpoint";
		merge_funnel_out = "/soc/funnel@3025000/out-ports/port/endpoint";
		replicator_in = "/soc/replicator@3026000/in-ports/port/endpoint";
		replicator_out0 = "/soc/replicator@3026000/out-ports/port@0/endpoint";
		replicator_out1 = "/soc/replicator@3026000/out-ports/port@1/endpoint";
		etf_in = "/soc/etf@3027000/in-ports/port/endpoint";
		etf_out = "/soc/etf@3027000/out-ports/port/endpoint";
		etr_in = "/soc/etr@3028000/in-ports/port/endpoint";
		etm0_out = "/soc/etm@3840000/out-ports/port/endpoint";
		etm1_out = "/soc/etm@3940000/out-ports/port/endpoint";
		apss_funnel0_in0 = "/soc/funnel@39b0000/in-ports/port@0/endpoint";
		apss_funnel0_in1 = "/soc/funnel@39b0000/in-ports/port@1/endpoint";
		apss_funnel0_out = "/soc/funnel@39b0000/out-ports/port/endpoint";
		etm2_out = "/soc/etm@3a40000/out-ports/port/endpoint";
		etm3_out = "/soc/etm@3b40000/out-ports/port/endpoint";
		apss_funnel1_in0 = "/soc/funnel@3bb0000/in-ports/port@0/endpoint";
		apss_funnel1_in1 = "/soc/funnel@3bb0000/in-ports/port@1/endpoint";
		apss_funnel1_out = "/soc/funnel@3bb0000/out-ports/port/endpoint";
		apss_merge_funnel_in0 = "/soc/funnel@3bc0000/in-ports/port@0/endpoint";
		apss_merge_funnel_in1 = "/soc/funnel@3bc0000/in-ports/port@1/endpoint";
		apss_merge_funnel_out = "/soc/funnel@3bc0000/out-ports/port/endpoint";
		kryocc = "/soc/clock-controller@6400000";
		usb3 = "/soc/usb@6af8800";
		usb3_dwc3 = "/soc/usb@6af8800/dwc3@6a00000";
		usb3phy = "/soc/phy@7410000";
		ssusb_phy_0 = "/soc/phy@7410000/phy@7410200";
		hsusb_phy1 = "/soc/phy@7411000";
		hsusb_phy2 = "/soc/phy@7412000";
		sdhc1 = "/soc/sdhci@7464900";
		sdhc2 = "/soc/sdhci@74a4900";
		blsp1_dma = "/soc/dma@7544000";
		blsp1_uart2 = "/soc/serial@7570000";
		blsp1_spi1 = "/soc/spi@7575000";
		blsp1_i2c3 = "/soc/i2c@7577000";
		blsp2_dma = "/soc/dma@7584000";
		blsp2_uart2 = "/soc/serial@75b0000";
		blsp2_uart3 = "/soc/serial@75b1000";
		blsp2_i2c1 = "/soc/i2c@75b5000";
		blsp2_i2c2 = "/soc/i2c@75b6000";
		blsp2_i2c5 = "/soc/i2c@75b9000";
		blsp2_i2c6 = "/soc/i2c@75ba000";
		blsp2_spi6 = "/soc/spi@75ba000";
		usb2 = "/soc/usb@76f8800";
		slimbam = "/soc/dma-controller@9184000";
		slim_msm = "/soc/slim@91c0000";
		tasha_ifd = "/soc/slim@91c0000/ngd@1/tas-ifd";
		wcd9335 = "/soc/slim@91c0000/ngd@1/codec@1";
		adsp_pil = "/soc/remoteproc@9300000";
		q6afe = "/soc/remoteproc@9300000/smd-edge/apr/q6afe";
		q6afedai = "/soc/remoteproc@9300000/smd-edge/apr/q6afe/dais";
		q6asm = "/soc/remoteproc@9300000/smd-edge/apr/q6asm";
		q6asmdai = "/soc/remoteproc@9300000/smd-edge/apr/q6asm/dais";
		q6adm = "/soc/remoteproc@9300000/smd-edge/apr/q6adm";
		q6routing = "/soc/remoteproc@9300000/smd-edge/apr/q6adm/routing";
		apcs_glb = "/soc/mailbox@9820000";
		saw3 = "/soc/syscon@9a10000";
		intc = "/soc/interrupt-controller@9bc0000";
		sound = "/sound";
		cpu0_alert0 = "/thermal-zones/cpu0-thermal/trips/trip-point0";
		cpu0_crit = "/thermal-zones/cpu0-thermal/trips/cpu_crit";
		cpu1_alert0 = "/thermal-zones/cpu1-thermal/trips/trip-point0";
		cpu1_crit = "/thermal-zones/cpu1-thermal/trips/cpu_crit";
		cpu2_alert0 = "/thermal-zones/cpu2-thermal/trips/trip-point0";
		cpu2_crit = "/thermal-zones/cpu2-thermal/trips/cpu_crit";
		cpu3_alert0 = "/thermal-zones/cpu3-thermal/trips/trip-point0";
		cpu3_crit = "/thermal-zones/cpu3-thermal/trips/cpu_crit";
		gpu1_alert0 = "/thermal-zones/gpu-thermal-top/trips/trip-point0";
		gpu2_alert0 = "/thermal-zones/gpu-thermal-bottom/trips/trip-point0";
		m4m_alert0 = "/thermal-zones/m4m-thermal/trips/trip-point0";
		l3_or_venus_alert0 = "/thermal-zones/l3-or-venus-thermal/trips/trip-point0";
		cluster0_l2_alert0 = "/thermal-zones/cluster0-l2-thermal/trips/trip-point0";
		cluster1_l2_alert0 = "/thermal-zones/cluster1-l2-thermal/trips/trip-point0";
		camera_alert0 = "/thermal-zones/camera-thermal/trips/trip-point0";
		q6_dsp_alert0 = "/thermal-zones/q6-dsp-thermal/trips/trip-point0";
		mem_alert0 = "/thermal-zones/mem-thermal/trips/trip-point0";
		modemtx_alert0 = "/thermal-zones/modemtx-thermal/trips/trip-point0";
		pm8994_alert0 = "/thermal-zones/pm8994-thermal/trips/pm8994-alert0";
		pm8994_crit = "/thermal-zones/pm8994-thermal/trips/pm8994-crit";
		usb2_id = "/usb2-id";
		usb3_id = "/usb3-id";
		vph_pwr = "/vph-pwr-regulator";
		wlan_en = "/wlan-en-1-8v";
	};
};
